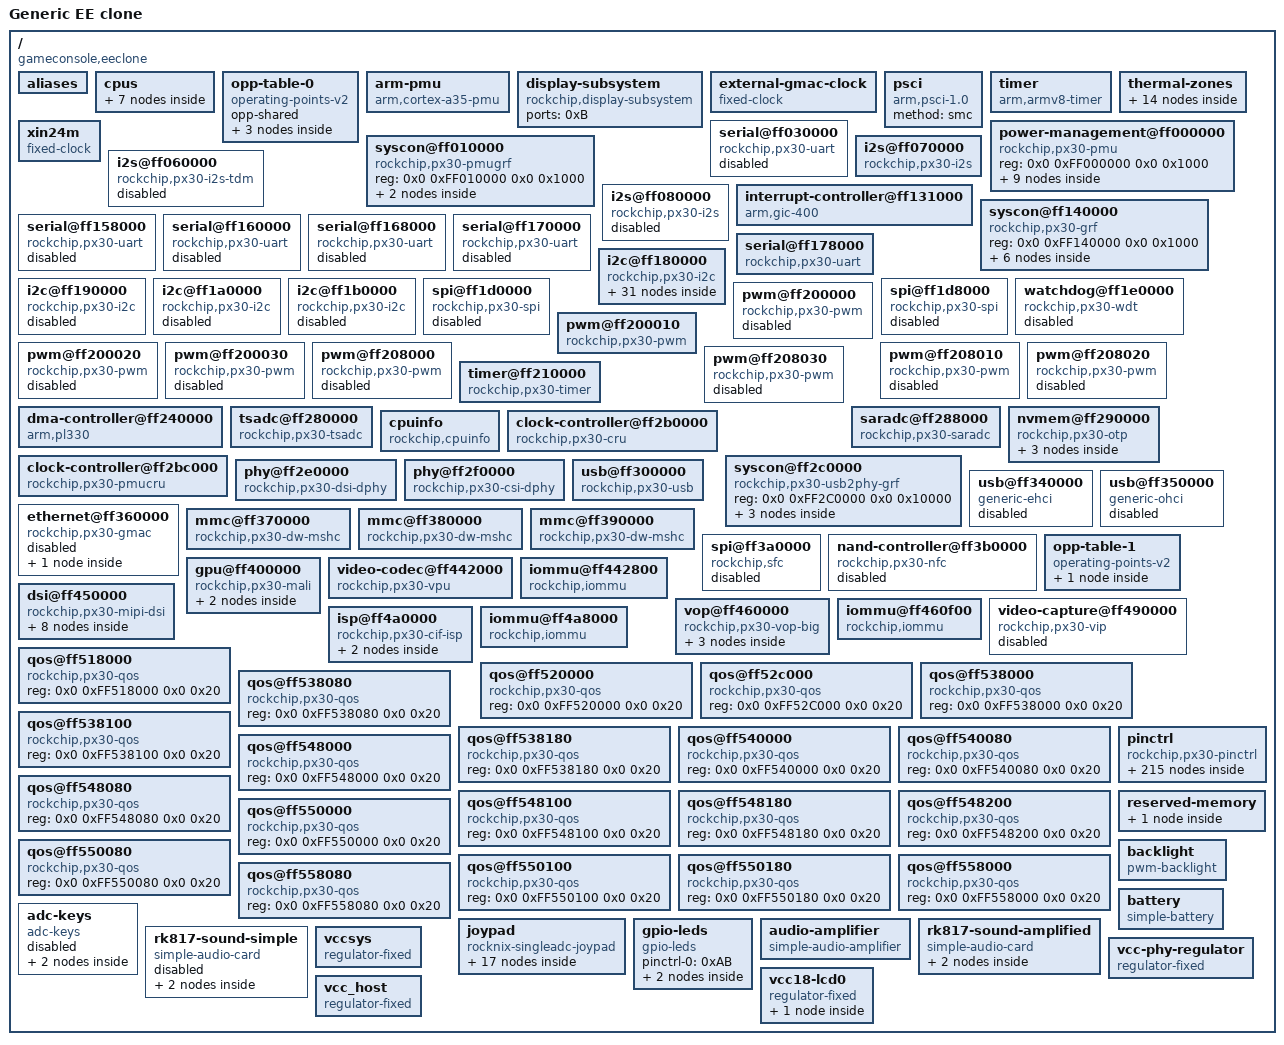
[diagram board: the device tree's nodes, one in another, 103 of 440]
/dts-v1/;
// version: 17
// last_comp_version: 16
// boot_cpuid_phys: 0x0

/ {
    compatible = "gameconsole,eeclone", "rockchip,rk3326";
    interrupt-parent = <0x1>;
    #address-cells = <0x2>;
    #size-cells = <0x2>;
    model = "Generic EE clone";
    aliases {
        i2c0 = "/i2c@ff180000";
        i2c1 = "/i2c@ff190000";
        i2c2 = "/i2c@ff1a0000";
        i2c3 = "/i2c@ff1b0000";
        serial0 = "/serial@ff030000";
        serial1 = "/serial@ff160000";
        serial2 = "/serial@ff178000";
        serial3 = "/serial@ff168000";
        serial4 = "/serial@ff170000";
        serial5 = "/serial@ff178000";
        spi0 = "/spi@ff1d0000";
        spi1 = "/spi@ff1d8000";
        mmc0 = "/mmc@ff390000";
        mmc1 = "/mmc@ff370000";
        mmc2 = "/mmc@ff380000";
    };
    cpus {
        #address-cells = <0x2>;
        #size-cells = <0x0>;
        cpu@0 {
            device_type = "cpu";
            compatible = "arm,cortex-a35";
            reg = <0x0 0x0>;
            enable-method = "psci";
            clocks = <0x2 0x7>;
            #cooling-cells = <0x2>;
            cpu-idle-states = <0x3 0x4>;
            dynamic-power-coefficient = <0x5A>;
            operating-points-v2 = <0x5>;
            cpu-supply = <0x6>;
            phandle = <0x7>;
        };
        cpu@1 {
            device_type = "cpu";
            compatible = "arm,cortex-a35";
            reg = <0x0 0x1>;
            enable-method = "psci";
            clocks = <0x2 0x7>;
            #cooling-cells = <0x2>;
            cpu-idle-states = <0x3 0x4>;
            dynamic-power-coefficient = <0x5A>;
            operating-points-v2 = <0x5>;
            cpu-supply = <0x6>;
            phandle = <0x8>;
        };
        cpu@2 {
            device_type = "cpu";
            compatible = "arm,cortex-a35";
            reg = <0x0 0x2>;
            enable-method = "psci";
            clocks = <0x2 0x7>;
            #cooling-cells = <0x2>;
            cpu-idle-states = <0x3 0x4>;
            dynamic-power-coefficient = <0x5A>;
            operating-points-v2 = <0x5>;
            cpu-supply = <0x6>;
            phandle = <0x9>;
        };
        cpu@3 {
            device_type = "cpu";
            compatible = "arm,cortex-a35";
            reg = <0x0 0x3>;
            enable-method = "psci";
            clocks = <0x2 0x7>;
            #cooling-cells = <0x2>;
            cpu-idle-states = <0x3 0x4>;
            dynamic-power-coefficient = <0x5A>;
            operating-points-v2 = <0x5>;
            cpu-supply = <0x6>;
            phandle = <0xA>;
        };
        idle-states {
            entry-method = "psci";
            cpu-sleep {
                compatible = "arm,idle-state";
                local-timer-stop;
                arm,psci-suspend-param = <0x10000>;
                entry-latency-us = <0x78>;
                exit-latency-us = <0xFA>;
                min-residency-us = <0x384>;
                phandle = <0x3>;
            };
            cluster-sleep {
                compatible = "arm,idle-state";
                local-timer-stop;
                arm,psci-suspend-param = <0x1010000>;
                entry-latency-us = <0x190>;
                exit-latency-us = <0x1F4>;
                min-residency-us = <0x7D0>;
                phandle = <0x4>;
            };
        };
    };
    opp-table-0 {
        compatible = "operating-points-v2";
        opp-shared;
        phandle = <0x5>;
        opp-1008000000 {
            opp-hz = <0x0 0x3C14DC00>;
            opp-microvolt = <0x11EDD8 0x11EDD8 0x149970>;
            clock-latency-ns = <0x9C40>;
        };
        opp-1296000000 {
            opp-hz = <0x0 0x4D3F6400>;
            opp-microvolt = <0x149970 0x149970 0x149970>;
            clock-latency-ns = <0x9C40>;
        };
        opp-1416000000 {
            opp-hz = <0x0 0x54667200>;
            opp-microvolt = <0x149970 0x149970 0x149970>;
            clock-latency-ns = <0x9C40>;
            turbo-mode;
        };
    };
    arm-pmu {
        compatible = "arm,cortex-a35-pmu";
        interrupts = <0x0 0x64 0x4 0x0 0x65 0x4 0x0 0x66 0x4 0x0 0x67 0x4>;
        interrupt-affinity = <0x7 0x8 0x9 0xA>;
    };
    display-subsystem {
        compatible = "rockchip,display-subsystem";
        ports = <0xB>;
        status = "okay";
        phandle = <0xB4>;
    };
    external-gmac-clock {
        compatible = "fixed-clock";
        clock-frequency = <0x2FAF080>;
        clock-output-names = "gmac_clkin";
        #clock-cells = <0x0>;
        phandle = <0xB5>;
    };
    psci {
        compatible = "arm,psci-1.0";
        method = "smc";
    };
    timer {
        compatible = "arm,armv8-timer";
        interrupts = <0x1 0xD 0xF04 0x1 0xE 0xF04 0x1 0xB 0xF04 0x1 0xA 0xF04>;
    };
    thermal-zones {
        phandle = <0xB6>;
        soc-thermal {
            polling-delay-passive = <0x14>;
            polling-delay = <0x3E8>;
            sustainable-power = <0x2EE>;
            thermal-sensors = <0xC 0x0>;
            phandle = <0xB7>;
            trips {
                trip-point-0 {
                    temperature = <0x11170>;
                    hysteresis = <0x7D0>;
                    type = "passive";
                    phandle = <0xB8>;
                };
                trip-point-1 {
                    temperature = <0x14C08>;
                    hysteresis = <0x7D0>;
                    type = "passive";
                    phandle = <0xD>;
                };
                soc-crit {
                    temperature = <0x1C138>;
                    hysteresis = <0x7D0>;
                    type = "critical";
                    phandle = <0xB9>;
                };
            };
            cooling-maps {
                map0 {
                    trip = <0xD>;
                    cooling-device = <0x7 0xFFFFFFFF 0xFFFFFFFF>;
                    contribution = <0x1000>;
                };
            };
        };
        gpu-thermal {
            polling-delay-passive = <0x64>;
            polling-delay = <0x3E8>;
            thermal-sensors = <0xC 0x1>;
            phandle = <0xBA>;
            trips {
                gpu-threshold {
                    temperature = <0x11170>;
                    hysteresis = <0x7D0>;
                    type = "passive";
                    phandle = <0xBB>;
                };
                gpu-target {
                    temperature = <0x14C08>;
                    hysteresis = <0x7D0>;
                    type = "passive";
                    phandle = <0xE>;
                };
                gpu-crit {
                    temperature = <0x1C138>;
                    hysteresis = <0x7D0>;
                    type = "critical";
                    phandle = <0xBC>;
                };
            };
            cooling-maps {
                map0 {
                    trip = <0xE>;
                    cooling-device = <0xF 0xFFFFFFFF 0xFFFFFFFF>;
                };
            };
        };
    };
    xin24m {
        compatible = "fixed-clock";
        #clock-cells = <0x0>;
        clock-frequency = <0x16E3600>;
        clock-output-names = "xin24m";
        phandle = <0x6F>;
    };
    power-management@ff000000 {
        compatible = "rockchip,px30-pmu", "syscon", "simple-mfd";
        reg = <0x0 0xFF000000 0x0 0x1000>;
        phandle = <0xBD>;
        power-controller {
            compatible = "rockchip,px30-power-controller";
            #power-domain-cells = <0x1>;
            #address-cells = <0x1>;
            #size-cells = <0x0>;
            phandle = <0x71>;
            power-domain@5 {
                reg = <0x5>;
                clocks = <0x2 0x103 0x2 0x102 0x2 0x3C>;
                pm_qos = <0x10 0x11>;
                #power-domain-cells = <0x0>;
            };
            power-domain@7 {
                reg = <0x7>;
                clocks = <0x2 0xF7 0x2 0x3B>;
                pm_qos = <0x12>;
                #power-domain-cells = <0x0>;
            };
            power-domain@9 {
                reg = <0x9>;
                clocks = <0x2 0xB2 0x2 0x143 0x2 0x40 0x2 0x3F>;
                pm_qos = <0x13>;
                #power-domain-cells = <0x0>;
            };
            power-domain@10 {
                reg = <0xA>;
                clocks = <0x2 0xFE 0x2 0x100 0x2 0xFF 0x2 0x101 0x2 0x39 0x2 0x37 0x2 0x38 0x2 0x3A>;
                pm_qos = <0x14 0x15 0x16 0x17>;
                #power-domain-cells = <0x0>;
            };
            power-domain@11 {
                reg = <0xB>;
                clocks = <0x2 0xAF 0x2 0xF4 0x2 0x4B>;
                pm_qos = <0x18 0x19>;
                #power-domain-cells = <0x0>;
            };
            power-domain@12 {
                reg = <0xC>;
                clocks = <0x2 0xB7 0x2 0xB5 0x2 0xB6 0x2 0x96 0x2 0x97 0x2 0xFD 0x2 0xFB 0x2 0xFC 0x2 0x144 0x2 0x35 0x2 0x36>;
                pm_qos = <0x1A 0x1B 0x1C 0x1D>;
                #power-domain-cells = <0x0>;
            };
            power-domain@13 {
                reg = <0xD>;
                clocks = <0x2 0xB3 0x2 0xB4 0x2 0xF9 0x2 0xFA 0x2 0x33>;
                pm_qos = <0x1E 0x1F 0x20 0x21 0x22>;
                #power-domain-cells = <0x0>;
            };
            power-domain@14 {
                reg = <0xE>;
                clocks = <0x2 0x49>;
                pm_qos = <0x23>;
                #power-domain-cells = <0x0>;
            };
        };
    };
    syscon@ff010000 {
        compatible = "rockchip,px30-pmugrf", "syscon", "simple-mfd";
        reg = <0x0 0xFF010000 0x0 0x1000>;
        phandle = <0x9C>;
        io-domains {
            compatible = "rockchip,px30-pmu-io-voltage-domain";
            status = "okay";
            pmuio1-supply = <0x24>;
            pmuio2-supply = <0x24>;
            phandle = <0xBE>;
        };
        reboot-mode {
            compatible = "syscon-reboot-mode";
            offset = <0x200>;
            mode-bootloader = <0x5242C301>;
            mode-fastboot = <0x5242C309>;
            mode-loader = <0x5242C301>;
            mode-normal = <0x5242C300>;
            mode-recovery = <0x5242C303>;
        };
    };
    serial@ff030000 {
        compatible = "rockchip,px30-uart", "snps,dw-apb-uart";
        reg = <0x0 0xFF030000 0x0 0x100>;
        interrupts = <0x0 0xF 0x4>;
        clocks = <0x25 0x6 0x25 0x15>;
        clock-names = "baudclk", "apb_pclk";
        dmas = <0x26 0x0 0x26 0x1>;
        dma-names = "tx", "rx";
        reg-shift = <0x2>;
        reg-io-width = <0x4>;
        pinctrl-names = "default";
        pinctrl-0 = <0x27 0x28 0x29>;
        status = "disabled";
        phandle = <0xBF>;
    };
    i2s@ff060000 {
        compatible = "rockchip,px30-i2s-tdm";
        reg = <0x0 0xFF060000 0x0 0x1000>;
        interrupts = <0x0 0xC 0x4>;
        clocks = <0x2 0x10 0x2 0x12 0x2 0x106>;
        clock-names = "mclk_tx", "mclk_rx", "hclk";
        dmas = <0x26 0x10 0x26 0x11>;
        dma-names = "tx", "rx";
        rockchip,grf = <0x2A>;
        resets = <0x2 0x84 0x2 0xBF>;
        reset-names = "tx-m", "rx-m";
        pinctrl-names = "default";
        pinctrl-0 = <0x2B 0x2C 0x2D 0x2E 0x2F 0x30 0x31 0x32 0x33 0x34 0x35 0x36>;
        #sound-dai-cells = <0x0>;
        status = "disabled";
        phandle = <0xC0>;
    };
    i2s@ff070000 {
        compatible = "rockchip,px30-i2s", "rockchip,rk3066-i2s";
        reg = <0x0 0xFF070000 0x0 0x1000>;
        interrupts = <0x0 0xD 0x4>;
        clocks = <0x2 0x14 0x2 0x107>;
        clock-names = "i2s_clk", "i2s_hclk";
        dmas = <0x26 0x12 0x26 0x13>;
        dma-names = "tx", "rx";
        pinctrl-names = "default";
        pinctrl-0 = <0x37 0x38 0x39 0x3A>;
        #sound-dai-cells = <0x0>;
        status = "okay";
        phandle = <0xB0>;
    };
    i2s@ff080000 {
        compatible = "rockchip,px30-i2s", "rockchip,rk3066-i2s";
        reg = <0x0 0xFF080000 0x0 0x1000>;
        interrupts = <0x0 0xE 0x4>;
        clocks = <0x2 0x16 0x2 0x108>;
        clock-names = "i2s_clk", "i2s_hclk";
        dmas = <0x26 0x14 0x26 0x15>;
        dma-names = "tx", "rx";
        pinctrl-names = "default";
        pinctrl-0 = <0x3B 0x3C 0x3D 0x3E>;
        #sound-dai-cells = <0x0>;
        status = "disabled";
        phandle = <0xC1>;
    };
    interrupt-controller@ff131000 {
        compatible = "arm,gic-400";
        #interrupt-cells = <0x3>;
        #address-cells = <0x0>;
        interrupt-controller;
        reg = <0x0 0xFF131000 0x0 0x1000 0x0 0xFF132000 0x0 0x2000 0x0 0xFF134000 0x0 0x2000 0x0 0xFF136000 0x0 0x2000>;
        interrupts = <0x1 0x9 0xF04>;
        phandle = <0x1>;
    };
    syscon@ff140000 {
        compatible = "rockchip,px30-grf", "syscon", "simple-mfd";
        reg = <0x0 0xFF140000 0x0 0x1000>;
        phandle = <0x2A>;
        io-domains {
            compatible = "rockchip,px30-io-voltage-domain";
            status = "okay";
            vccio1-supply = <0x3F>;
            vccio2-supply = <0x40>;
            vccio3-supply = <0x41>;
            vccio4-supply = <0x42>;
            vccio5-supply = <0x42>;
            vccio6-supply = <0x41>;
            phandle = <0xC2>;
        };
        lvds {
            compatible = "rockchip,px30-lvds";
            phys = <0x43>;
            phy-names = "dphy";
            rockchip,grf = <0x2A>;
            rockchip,output = "lvds";
            status = "disabled";
            phandle = <0xC3>;
            ports {
                #address-cells = <0x1>;
                #size-cells = <0x0>;
                port@0 {
                    reg = <0x0>;
                    #address-cells = <0x1>;
                    #size-cells = <0x0>;
                    phandle = <0xC4>;
                    endpoint@0 {
                        reg = <0x0>;
                        remote-endpoint = <0x44>;
                        phandle = <0x99>;
                    };
                };
                port@1 {
                    reg = <0x1>;
                    phandle = <0xC5>;
                };
            };
        };
    };
    serial@ff158000 {
        compatible = "rockchip,px30-uart", "snps,dw-apb-uart";
        reg = <0x0 0xFF158000 0x0 0x100>;
        interrupts = <0x0 0x10 0x4>;
        clocks = <0x2 0x18 0x2 0x149>;
        clock-names = "baudclk", "apb_pclk";
        dmas = <0x26 0x2 0x26 0x3>;
        dma-names = "tx", "rx";
        reg-shift = <0x2>;
        reg-io-width = <0x4>;
        pinctrl-names = "default";
        pinctrl-0 = <0x45 0x46 0x47>;
        status = "disabled";
        phandle = <0xC6>;
    };
    serial@ff160000 {
        compatible = "rockchip,px30-uart", "snps,dw-apb-uart";
        reg = <0x0 0xFF160000 0x0 0x100>;
        interrupts = <0x0 0x11 0x4>;
        clocks = <0x2 0x19 0x2 0x14A>;
        clock-names = "baudclk", "apb_pclk";
        dmas = <0x26 0x4 0x26 0x5>;
        dma-names = "tx", "rx";
        reg-shift = <0x2>;
        reg-io-width = <0x4>;
        pinctrl-names = "default";
        pinctrl-0 = <0x48>;
        status = "disabled";
        phandle = <0xC7>;
    };
    serial@ff168000 {
        compatible = "rockchip,px30-uart", "snps,dw-apb-uart";
        reg = <0x0 0xFF168000 0x0 0x100>;
        interrupts = <0x0 0x12 0x4>;
        clocks = <0x2 0x1A 0x2 0x14B>;
        clock-names = "baudclk", "apb_pclk";
        dmas = <0x26 0x6 0x26 0x7>;
        dma-names = "tx", "rx";
        reg-shift = <0x2>;
        reg-io-width = <0x4>;
        pinctrl-names = "default";
        pinctrl-0 = <0x49 0x4A 0x4B>;
        status = "disabled";
        phandle = <0xC8>;
    };
    serial@ff170000 {
        compatible = "rockchip,px30-uart", "snps,dw-apb-uart";
        reg = <0x0 0xFF170000 0x0 0x100>;
        interrupts = <0x0 0x13 0x4>;
        clocks = <0x2 0x1B 0x2 0x14C>;
        clock-names = "baudclk", "apb_pclk";
        dmas = <0x26 0x8 0x26 0x9>;
        dma-names = "tx", "rx";
        reg-shift = <0x2>;
        reg-io-width = <0x4>;
        pinctrl-names = "default";
        pinctrl-0 = <0x4C 0x4D 0x4E>;
        status = "disabled";
        phandle = <0xC9>;
    };
    serial@ff178000 {
        compatible = "rockchip,px30-uart", "snps,dw-apb-uart";
        reg = <0x0 0xFF178000 0x0 0x100>;
        interrupts = <0x0 0x14 0x4>;
        clocks = <0x2 0x1C 0x2 0x14D>;
        clock-names = "baudclk", "apb_pclk";
        dmas = <0x26 0xA 0x26 0xB>;
        dma-names = "tx", "rx";
        reg-shift = <0x2>;
        reg-io-width = <0x4>;
        pinctrl-names = "default";
        pinctrl-0 = <0x4F 0x50 0x51>;
        status = "okay";
        phandle = <0xCA>;
    };
    i2c@ff180000 {
        compatible = "rockchip,px30-i2c", "rockchip,rk3399-i2c";
        reg = <0x0 0xFF180000 0x0 0x1000>;
        clocks = <0x2 0x1D 0x2 0x14E>;
        clock-names = "i2c", "pclk";
        interrupts = <0x0 0x7 0x4>;
        pinctrl-names = "default";
        pinctrl-0 = <0x52>;
        #address-cells = <0x1>;
        #size-cells = <0x0>;
        status = "okay";
        clock-frequency = <0x61A80>;
        i2c-scl-falling-time-ns = <0x10>;
        i2c-scl-rising-time-ns = <0x118>;
        phandle = <0xCB>;
        pmic@20 {
            compatible = "rockchip,rk817";
            reg = <0x20>;
            interrupt-parent = <0x53>;
            interrupts = <0xA 0x8>;
            clock-output-names = "rk808-clkout1", "xin32k";
            clock-names = "mclk";
            clocks = <0x2 0x15>;
            pinctrl-names = "default";
            pinctrl-0 = <0x54 0x55>;
            rockchip,system-power-controller;
            wakeup-source;
            #clock-cells = <0x1>;
            #sound-dai-cells = <0x0>;
            vcc1-supply = <0x56>;
            vcc2-supply = <0x56>;
            vcc3-supply = <0x56>;
            vcc4-supply = <0x56>;
            vcc5-supply = <0x56>;
            vcc6-supply = <0x56>;
            vcc7-supply = <0x42>;
            vcc8-supply = <0x56>;
            phandle = <0xAF>;
            regulators {
                DCDC_REG1 {
                    regulator-name = "vdd_logic";
                    regulator-min-microvolt = <0xE7EF0>;
                    regulator-max-microvolt = <0x149970>;
                    regulator-initial-mode = <0x2>;
                    regulator-ramp-delay = <0x1771>;
                    regulator-always-on;
                    regulator-boot-on;
                    phandle = <0x8E>;
                    regulator-state-mem {
                        regulator-on-in-suspend;
                        regulator-suspend-microvolt = <0xE7EF0>;
                    };
                };
                DCDC_REG2 {
                    regulator-name = "vdd_arm";
                    regulator-min-microvolt = <0xCF850>;
                    regulator-max-microvolt = <0x149970>;
                    regulator-ramp-delay = <0x1771>;
                    regulator-initial-mode = <0x2>;
                    regulator-always-on;
                    regulator-boot-on;
                    phandle = <0x6>;
                    regulator-state-mem {
                        regulator-off-in-suspend;
                        regulator-suspend-microvolt = <0xE7EF0>;
                    };
                };
                DCDC_REG3 {
                    regulator-name = "vcc_ddr";
                    regulator-always-on;
                    regulator-boot-on;
                    regulator-initial-mode = <0x2>;
                    phandle = <0xCC>;
                    regulator-state-mem {
                        regulator-on-in-suspend;
                    };
                };
                DCDC_REG4 {
                    regulator-name = "vcc_3v0";
                    regulator-min-microvolt = <0x2DC6C0>;
                    regulator-max-microvolt = <0x2DC6C0>;
                    regulator-initial-mode = <0x2>;
                    regulator-always-on;
                    regulator-boot-on;
                    phandle = <0x42>;
                    regulator-state-mem {
                        regulator-off-in-suspend;
                        regulator-suspend-microvolt = <0x2DC6C0>;
                    };
                };
                LDO_REG1 {
                    regulator-name = "vcc_1v0";
                    regulator-always-on;
                    regulator-boot-on;
                    regulator-min-microvolt = <0xF4240>;
                    regulator-max-microvolt = <0xF4240>;
                    phandle = <0xCD>;
                    regulator-state-mem {
                        regulator-on-in-suspend;
                        regulator-suspend-microvolt = <0xF4240>;
                    };
                };
                LDO_REG2 {
                    regulator-name = "vcc1v8_soc";
                    regulator-min-microvolt = <0x1B7740>;
                    regulator-max-microvolt = <0x1B7740>;
                    regulator-always-on;
                    regulator-boot-on;
                    phandle = <0x41>;
                    regulator-state-mem {
                        regulator-on-in-suspend;
                        regulator-suspend-microvolt = <0x1B7740>;
                    };
                };
                LDO_REG3 {
                    regulator-name = "vcc1v0_soc";
                    regulator-min-microvolt = <0xF4240>;
                    regulator-max-microvolt = <0xF4240>;
                    regulator-always-on;
                    regulator-boot-on;
                    phandle = <0xCE>;
                    regulator-state-mem {
                        regulator-on-in-suspend;
                        regulator-suspend-microvolt = <0xF4240>;
                    };
                };
                LDO_REG4 {
                    regulator-name = "vcc3v0_pmu";
                    regulator-min-microvolt = <0x2DC6C0>;
                    regulator-max-microvolt = <0x2DC6C0>;
                    regulator-always-on;
                    regulator-boot-on;
                    phandle = <0x24>;
                    regulator-state-mem {
                        regulator-on-in-suspend;
                        regulator-suspend-microvolt = <0x2DC6C0>;
                    };
                };
                LDO_REG5 {
                    regulator-name = "vccio_sd";
                    regulator-min-microvolt = <0x1B7740>;
                    regulator-max-microvolt = <0x325AA0>;
                    regulator-always-on;
                    regulator-boot-on;
                    phandle = <0x40>;
                    regulator-state-mem {
                        regulator-on-in-suspend;
                        regulator-suspend-microvolt = <0x325AA0>;
                    };
                };
                LDO_REG6 {
                    regulator-name = "vcc_sd";
                    regulator-min-microvolt = <0x1B7740>;
                    regulator-max-microvolt = <0x325AA0>;
                    phandle = <0x7A>;
                    regulator-state-mem {
                        regulator-on-in-suspend;
                        regulator-suspend-microvolt = <0x325AA0>;
                    };
                };
                LDO_REG7 {
                    regulator-name = "vcc2v8_dvp";
                    regulator-min-microvolt = <0x1B7740>;
                    regulator-max-microvolt = <0x325AA0>;
                    regulator-always-on;
                    regulator-boot-on;
                    phandle = <0x3F>;
                    regulator-state-mem {
                        regulator-off-in-suspend;
                        regulator-suspend-microvolt = <0x325AA0>;
                    };
                };
                LDO_REG8 {
                    regulator-name = "vcc3v0_dvp";
                    regulator-min-microvolt = <0x2DC6C0>;
                    regulator-max-microvolt = <0x2DC6C0>;
                    regulator-always-on;
                    regulator-boot-on;
                    phandle = <0x7E>;
                    regulator-state-mem {
                        regulator-on-in-suspend;
                        regulator-suspend-microvolt = <0x2DC6C0>;
                    };
                };
                LDO_REG9 {
                    regulator-min-microvolt = <0x16E360>;
                    regulator-max-microvolt = <0x16E360>;
                    regulator-name = "vdd1v5_dvp";
                    regulator-always-on;
                    regulator-boot-on;
                    phandle = <0xCF>;
                    regulator-state-mem {
                        regulator-off-in-suspend;
                        regulator-suspend-microvolt = <0x16E360>;
                    };
                };
                BOOST {
                    regulator-name = "usb_midu";
                    regulator-min-microvolt = <0x4AC4A0>;
                    regulator-max-microvolt = <0x5265C0>;
                    regulator-always-on;
                    regulator-boot-on;
                    phandle = <0xB3>;
                };
            };
            charger {
                monitored-battery = <0x57>;
                rockchip,resistor-sense-micro-ohms = <0x2710>;
                rockchip,sleep-enter-current-microamp = <0x493E0>;
                rockchip,sleep-filter-current-microamp = <0x186A0>;
                phandle = <0xD0>;
            };
            codec {
                rockchip,mic-in-differential;
                phandle = <0xD1>;
            };
        };
    };
    i2c@ff190000 {
        compatible = "rockchip,px30-i2c", "rockchip,rk3399-i2c";
        reg = <0x0 0xFF190000 0x0 0x1000>;
        clocks = <0x2 0x1E 0x2 0x14F>;
        clock-names = "i2c", "pclk";
        interrupts = <0x0 0x8 0x4>;
        pinctrl-names = "default";
        pinctrl-0 = <0x58>;
        #address-cells = <0x1>;
        #size-cells = <0x0>;
        status = "disabled";
        phandle = <0xD2>;
    };
    i2c@ff1a0000 {
        compatible = "rockchip,px30-i2c", "rockchip,rk3399-i2c";
        reg = <0x0 0xFF1A0000 0x0 0x1000>;
        clocks = <0x2 0x1F 0x2 0x150>;
        clock-names = "i2c", "pclk";
        interrupts = <0x0 0x9 0x4>;
        pinctrl-names = "default";
        pinctrl-0 = <0x59>;
        #address-cells = <0x1>;
        #size-cells = <0x0>;
        status = "disabled";
        phandle = <0xD3>;
    };
    i2c@ff1b0000 {
        compatible = "rockchip,px30-i2c", "rockchip,rk3399-i2c";
        reg = <0x0 0xFF1B0000 0x0 0x1000>;
        clocks = <0x2 0x20 0x2 0x151>;
        clock-names = "i2c", "pclk";
        interrupts = <0x0 0xA 0x4>;
        pinctrl-names = "default";
        pinctrl-0 = <0x5A>;
        #address-cells = <0x1>;
        #size-cells = <0x0>;
        status = "disabled";
        phandle = <0xD4>;
    };
    spi@ff1d0000 {
        compatible = "rockchip,px30-spi", "rockchip,rk3066-spi";
        reg = <0x0 0xFF1D0000 0x0 0x1000>;
        interrupts = <0x0 0x1A 0x4>;
        clocks = <0x2 0x24 0x2 0x155>;
        clock-names = "spiclk", "apb_pclk";
        dmas = <0x26 0xC 0x26 0xD>;
        dma-names = "tx", "rx";
        num-cs = <0x2>;
        pinctrl-names = "default";
        pinctrl-0 = <0x5B 0x5C 0x5D 0x5E>;
        #address-cells = <0x1>;
        #size-cells = <0x0>;
        status = "disabled";
        phandle = <0xD5>;
    };
    spi@ff1d8000 {
        compatible = "rockchip,px30-spi", "rockchip,rk3066-spi";
        reg = <0x0 0xFF1D8000 0x0 0x1000>;
        interrupts = <0x0 0x1B 0x4>;
        clocks = <0x2 0x25 0x2 0x156>;
        clock-names = "spiclk", "apb_pclk";
        dmas = <0x26 0xE 0x26 0xF>;
        dma-names = "tx", "rx";
        num-cs = <0x2>;
        pinctrl-names = "default";
        pinctrl-0 = <0x5F 0x60 0x61 0x62 0x63>;
        #address-cells = <0x1>;
        #size-cells = <0x0>;
        status = "disabled";
        phandle = <0xD6>;
    };
    watchdog@ff1e0000 {
        compatible = "rockchip,px30-wdt", "snps,dw-wdt";
        reg = <0x0 0xFF1E0000 0x0 0x100>;
        clocks = <0x2 0x15B>;
        interrupts = <0x0 0x25 0x4>;
        status = "disabled";
        phandle = <0xD7>;
    };
    pwm@ff200000 {
        compatible = "rockchip,px30-pwm", "rockchip,rk3328-pwm";
        reg = <0x0 0xFF200000 0x0 0x10>;
        clocks = <0x2 0x22 0x2 0x153>;
        clock-names = "pwm", "pclk";
        pinctrl-names = "default";
        pinctrl-0 = <0x64>;
        #pwm-cells = <0x3>;
        status = "disabled";
        phandle = <0xD8>;
    };
    pwm@ff200010 {
        compatible = "rockchip,px30-pwm", "rockchip,rk3328-pwm";
        reg = <0x0 0xFF200010 0x0 0x10>;
        clocks = <0x2 0x22 0x2 0x153>;
        clock-names = "pwm", "pclk";
        pinctrl-names = "default";
        pinctrl-0 = <0x65>;
        #pwm-cells = <0x3>;
        status = "okay";
        phandle = <0xA7>;
    };
    pwm@ff200020 {
        compatible = "rockchip,px30-pwm", "rockchip,rk3328-pwm";
        reg = <0x0 0xFF200020 0x0 0x10>;
        clocks = <0x2 0x22 0x2 0x153>;
        clock-names = "pwm", "pclk";
        pinctrl-names = "default";
        pinctrl-0 = <0x66>;
        #pwm-cells = <0x3>;
        status = "disabled";
        phandle = <0xD9>;
    };
    pwm@ff200030 {
        compatible = "rockchip,px30-pwm", "rockchip,rk3328-pwm";
        reg = <0x0 0xFF200030 0x0 0x10>;
        clocks = <0x2 0x22 0x2 0x153>;
        clock-names = "pwm", "pclk";
        pinctrl-names = "default";
        pinctrl-0 = <0x67>;
        #pwm-cells = <0x3>;
        status = "disabled";
        phandle = <0xDA>;
    };
    pwm@ff208000 {
        compatible = "rockchip,px30-pwm", "rockchip,rk3328-pwm";
        reg = <0x0 0xFF208000 0x0 0x10>;
        clocks = <0x2 0x23 0x2 0x154>;
        clock-names = "pwm", "pclk";
        pinctrl-names = "default";
        pinctrl-0 = <0x68>;
        #pwm-cells = <0x3>;
        status = "disabled";
        phandle = <0xDB>;
    };
    pwm@ff208010 {
        compatible = "rockchip,px30-pwm", "rockchip,rk3328-pwm";
        reg = <0x0 0xFF208010 0x0 0x10>;
        clocks = <0x2 0x23 0x2 0x154>;
        clock-names = "pwm", "pclk";
        pinctrl-names = "default";
        pinctrl-0 = <0x69>;
        #pwm-cells = <0x3>;
        status = "disabled";
        phandle = <0xDC>;
    };
    pwm@ff208020 {
        compatible = "rockchip,px30-pwm", "rockchip,rk3328-pwm";
        reg = <0x0 0xFF208020 0x0 0x10>;
        clocks = <0x2 0x23 0x2 0x154>;
        clock-names = "pwm", "pclk";
        pinctrl-names = "default";
        pinctrl-0 = <0x6A>;
        #pwm-cells = <0x3>;
        status = "disabled";
        phandle = <0xDD>;
    };
    pwm@ff208030 {
        compatible = "rockchip,px30-pwm", "rockchip,rk3328-pwm";
        reg = <0x0 0xFF208030 0x0 0x10>;
        clocks = <0x2 0x23 0x2 0x154>;
        clock-names = "pwm", "pclk";
        pinctrl-names = "default";
        pinctrl-0 = <0x6B>;
        #pwm-cells = <0x3>;
        status = "disabled";
        phandle = <0xDE>;
    };
    timer@ff210000 {
        compatible = "rockchip,px30-timer", "rockchip,rk3288-timer";
        reg = <0x0 0xFF210000 0x0 0x1000>;
        interrupts = <0x0 0x1E 0x4>;
        clocks = <0x2 0x159 0x2 0x26>;
        clock-names = "pclk", "timer";
        phandle = <0xDF>;
    };
    dma-controller@ff240000 {
        compatible = "arm,pl330", "arm,primecell";
        reg = <0x0 0xFF240000 0x0 0x4000>;
        interrupts = <0x0 0x1 0x4 0x0 0x2 0x4>;
        arm,pl330-periph-burst;
        clocks = <0x2 0xBB>;
        clock-names = "apb_pclk";
        #dma-cells = <0x1>;
        phandle = <0x26>;
    };
    tsadc@ff280000 {
        compatible = "rockchip,px30-tsadc";
        reg = <0x0 0xFF280000 0x0 0x100>;
        interrupts = <0x0 0x24 0x4>;
        assigned-clocks = <0x2 0x2C>;
        assigned-clock-rates = <0xC350>;
        clocks = <0x2 0x2C 0x2 0x158>;
        clock-names = "tsadc", "apb_pclk";
        resets = <0x2 0xA8>;
        reset-names = "tsadc-apb";
        rockchip,grf = <0x2A>;
        rockchip,hw-tshut-temp = <0x1D4C0>;
        pinctrl-names = "init", "default", "sleep";
        pinctrl-0 = <0x6C>;
        pinctrl-1 = <0x6D>;
        pinctrl-2 = <0x6C>;
        #thermal-sensor-cells = <0x1>;
        status = "okay";
        phandle = <0xC>;
    };
    saradc@ff288000 {
        compatible = "rockchip,px30-saradc", "rockchip,rk3399-saradc";
        reg = <0x0 0xFF288000 0x0 0x100>;
        interrupts = <0x0 0x54 0x4>;
        #io-channel-cells = <0x1>;
        clocks = <0x2 0x2D 0x2 0x157>;
        clock-names = "saradc", "apb_pclk";
        resets = <0x2 0xA5>;
        reset-names = "saradc-apb";
        status = "okay";
        vref-supply = <0x41>;
        phandle = <0xA8>;
    };
    nvmem@ff290000 {
        compatible = "rockchip,px30-otp";
        reg = <0x0 0xFF290000 0x0 0x4000>;
        clocks = <0x2 0x2F 0x2 0x15A 0x2 0x161>;
        clock-names = "otp", "apb_pclk", "phy";
        resets = <0x2 0xB4>;
        reset-names = "phy";
        #address-cells = <0x1>;
        #size-cells = <0x1>;
        phandle = <0xE0>;
        id@7 {
            reg = <0x7 0x10>;
            phandle = <0x6E>;
        };
        cpu-leakage@17 {
            reg = <0x17 0x1>;
            phandle = <0xE1>;
        };
        performance@1e {
            reg = <0x1E 0x1>;
            bits = <0x4 0x3>;
            phandle = <0xE2>;
        };
    };
    cpuinfo {
        compatible = "rockchip,cpuinfo";
        nvmem-cells = <0x6E>;
        nvmem-cell-names = "id";
    };
    clock-controller@ff2b0000 {
        compatible = "rockchip,px30-cru";
        reg = <0x0 0xFF2B0000 0x0 0x1000>;
        clocks = <0x6F 0x25 0x1>;
        clock-names = "xin24m", "gpll";
        rockchip,grf = <0x2A>;
        #clock-cells = <0x1>;
        #reset-cells = <0x1>;
        assigned-clocks = <0x2 0x4 0x2 0xAB 0x2 0xB0 0x2 0xF0 0x2 0xF5 0x2 0x140 0x2 0x49>;
        assigned-clock-rates = <0x46CF7100 0xBEBC200 0xBEBC200 0x8F0D180 0x8F0D180 0x5F5E100 0xBEBC200>;
        phandle = <0x2>;
    };
    clock-controller@ff2bc000 {
        compatible = "rockchip,px30-pmucru";
        reg = <0x0 0xFF2BC000 0x0 0x1000>;
        clocks = <0x6F>;
        clock-names = "xin24m";
        rockchip,grf = <0x2A>;
        #clock-cells = <0x1>;
        #reset-cells = <0x1>;
        assigned-clocks = <0x25 0x1 0x25 0x8 0x25 0x5>;
        assigned-clock-rates = <0x47868C00 0x5F5E100 0x18CBA80>;
        phandle = <0x25>;
    };
    syscon@ff2c0000 {
        compatible = "rockchip,px30-usb2phy-grf", "syscon", "simple-mfd";
        reg = <0x0 0xFF2C0000 0x0 0x10000>;
        #address-cells = <0x1>;
        #size-cells = <0x1>;
        phandle = <0xE3>;
        usb2phy@100 {
            compatible = "rockchip,px30-usb2phy";
            reg = <0x100 0x20>;
            clocks = <0x25 0xA>;
            clock-names = "phyclk";
            #clock-cells = <0x0>;
            assigned-clocks = <0x2 0xE>;
            assigned-clock-parents = <0x70>;
            clock-output-names = "usb480m_phy";
            status = "okay";
            phandle = <0x70>;
            host-port {
                #phy-cells = <0x0>;
                interrupts = <0x0 0x44 0x4>;
                interrupt-names = "linestate";
                status = "okay";
                phandle = <0x73>;
            };
            otg-port {
                #phy-cells = <0x0>;
                interrupts = <0x0 0x42 0x4 0x0 0x41 0x4 0x0 0x40 0x4>;
                interrupt-names = "otg-bvalid", "otg-id", "linestate";
                status = "disabled";
                phandle = <0x72>;
            };
        };
    };
    phy@ff2e0000 {
        compatible = "rockchip,px30-dsi-dphy";
        reg = <0x0 0xFF2E0000 0x0 0x10000>;
        clocks = <0x25 0xB 0x2 0x145>;
        clock-names = "ref", "pclk";
        resets = <0x2 0x3E>;
        reset-names = "apb";
        #phy-cells = <0x0>;
        power-domains = <0x71 0xC>;
        status = "okay";
        phandle = <0x43>;
    };
    phy@ff2f0000 {
        compatible = "rockchip,px30-csi-dphy";
        reg = <0x0 0xFF2F0000 0x0 0x4000>;
        clocks = <0x2 0x146>;
        clock-names = "pclk";
        #phy-cells = <0x0>;
        power-domains = <0x71 0xD>;
        resets = <0x2 0x2F>;
        reset-names = "apb";
        rockchip,grf = <0x2A>;
        status = "okay";
        phandle = <0x9B>;
    };
    usb@ff300000 {
        compatible = "rockchip,px30-usb", "rockchip,rk3066-usb", "snps,dwc2";
        reg = <0x0 0xFF300000 0x0 0x40000>;
        interrupts = <0x0 0x3E 0x4>;
        clocks = <0x2 0x102>;
        clock-names = "otg";
        dr_mode = "otg";
        g-np-tx-fifo-size = <0x10>;
        g-rx-fifo-size = <0x118>;
        g-tx-fifo-size = <0x100 0x80 0x80 0x40 0x20 0x10>;
        phys = <0x72>;
        phy-names = "usb2-phy";
        power-domains = <0x71 0x5>;
        status = "okay";
        usb-role-switch;
        role-switch-default-mode = "host";
        phandle = <0xE4>;
    };
    usb@ff340000 {
        compatible = "generic-ehci";
        reg = <0x0 0xFF340000 0x0 0x10000>;
        interrupts = <0x0 0x3C 0x4>;
        clocks = <0x2 0x103>;
        phys = <0x73>;
        phy-names = "usb";
        power-domains = <0x71 0x5>;
        status = "disabled";
        phandle = <0xE5>;
    };
    usb@ff350000 {
        compatible = "generic-ohci";
        reg = <0x0 0xFF350000 0x0 0x10000>;
        interrupts = <0x0 0x3D 0x4>;
        clocks = <0x2 0x103>;
        phys = <0x73>;
        phy-names = "usb";
        power-domains = <0x71 0x5>;
        status = "disabled";
        phandle = <0xE6>;
    };
    ethernet@ff360000 {
        compatible = "rockchip,px30-gmac";
        reg = <0x0 0xFF360000 0x0 0x10000>;
        interrupts = <0x0 0x2B 0x4>;
        interrupt-names = "macirq";
        clocks = <0x2 0x3E 0x2 0x3F 0x2 0x3F 0x2 0x40 0x2 0x41 0x2 0xB2 0x2 0x143 0x2 0x4C>;
        clock-names = "stmmaceth", "mac_clk_rx", "mac_clk_tx", "clk_mac_ref", "clk_mac_refout", "aclk_mac", "pclk_mac", "clk_mac_speed";
        rockchip,grf = <0x2A>;
        phy-mode = "rmii";
        pinctrl-names = "default";
        pinctrl-0 = <0x74 0x75>;
        power-domains = <0x71 0x9>;
        resets = <0x2 0x5E>;
        reset-names = "stmmaceth";
        status = "disabled";
        phandle = <0xE7>;
        mdio {
            compatible = "snps,dwmac-mdio";
            #address-cells = <0x1>;
            #size-cells = <0x0>;
            phandle = <0xE8>;
        };
    };
    mmc@ff370000 {
        compatible = "rockchip,px30-dw-mshc", "rockchip,rk3288-dw-mshc";
        reg = <0x0 0xFF370000 0x0 0x4000>;
        interrupts = <0x0 0x36 0x4>;
        clocks = <0x2 0xF7 0x2 0x3B 0x2 0x43 0x2 0x44>;
        clock-names = "biu", "ciu", "ciu-drive", "ciu-sample";
        bus-width = <0x4>;
        fifo-depth = <0x100>;
        max-frequency = <0x8F0D180>;
        pinctrl-names = "default";
        pinctrl-0 = <0x76 0x77 0x78 0x79>;
        power-domains = <0x71 0x7>;
        status = "okay";
        cap-sd-highspeed;
        card-detect-delay = <0x320>;
        cd-gpios = <0x53 0x3 0x1>;
        sd-uhs-sdr12;
        sd-uhs-sdr25;
        sd-uhs-sdr50;
        sd-uhs-sdr104;
        vqmmc-supply = <0x40>;
        vmmc-supply = <0x7A>;
        phandle = <0xE9>;
    };
    mmc@ff380000 {
        compatible = "rockchip,px30-dw-mshc", "rockchip,rk3288-dw-mshc";
        reg = <0x0 0xFF380000 0x0 0x4000>;
        interrupts = <0x0 0x37 0x4>;
        clocks = <0x2 0xFF 0x2 0x38 0x2 0x45 0x2 0x46>;
        clock-names = "biu", "ciu", "ciu-drive", "ciu-sample";
        bus-width = <0x4>;
        fifo-depth = <0x100>;
        max-frequency = <0x5F5E100>;
        pinctrl-names = "default";
        pinctrl-0 = <0x7B 0x7C 0x7D>;
        power-domains = <0x71 0xA>;
        status = "okay";
        cap-sd-highspeed;
        cd-gpios = <0x53 0x2 0x1>;
        card-detect-delay = <0x320>;
        sd-uhs-sdr12;
        sd-uhs-sdr25;
        sd-uhs-sdr50;
        sd-uhs-sdr104;
        vqmmc-supply = <0x3F>;
        vmmc-supply = <0x7E>;
        phandle = <0xEA>;
    };
    mmc@ff390000 {
        compatible = "rockchip,px30-dw-mshc", "rockchip,rk3288-dw-mshc";
        reg = <0x0 0xFF390000 0x0 0x4000>;
        interrupts = <0x0 0x35 0x4>;
        clocks = <0x2 0x100 0x2 0x39 0x2 0x47 0x2 0x48>;
        clock-names = "biu", "ciu", "ciu-drive", "ciu-sample";
        bus-width = <0x8>;
        fifo-depth = <0x100>;
        max-frequency = <0x8F0D180>;
        pinctrl-names = "default";
        pinctrl-0 = <0x7F 0x80 0x81>;
        power-domains = <0x71 0xA>;
        status = "okay";
        no-sdio;
        no-sd;
        disable-wp;
        non-removable;
        num-slots = <0x1>;
        phandle = <0xEB>;
    };
    spi@ff3a0000 {
        compatible = "rockchip,sfc";
        reg = <0x0 0xFF3A0000 0x0 0x4000>;
        interrupts = <0x0 0x38 0x4>;
        clocks = <0x2 0x3A 0x2 0x101>;
        clock-names = "clk_sfc", "hclk_sfc";
        pinctrl-0 = <0x82 0x83 0x84>;
        pinctrl-names = "default";
        power-domains = <0x71 0xA>;
        status = "disabled";
        phandle = <0xEC>;
    };
    nand-controller@ff3b0000 {
        compatible = "rockchip,px30-nfc";
        reg = <0x0 0xFF3B0000 0x0 0x4000>;
        interrupts = <0x0 0x39 0x4>;
        clocks = <0x2 0xFE 0x2 0x37>;
        clock-names = "ahb", "nfc";
        assigned-clocks = <0x2 0x37>;
        assigned-clock-rates = <0x8F0D180>;
        pinctrl-names = "default";
        pinctrl-0 = <0x85 0x86 0x87 0x88 0x89 0x8A 0x8B 0x8C>;
        power-domains = <0x71 0xA>;
        status = "disabled";
        phandle = <0xED>;
    };
    opp-table-1 {
        compatible = "operating-points-v2";
        phandle = <0x8D>;
        opp-560000000 {
            opp-hz = <0x0 0x2160EC00>;
            opp-microvolt = <0x118C30>;
        };
    };
    gpu@ff400000 {
        compatible = "rockchip,px30-mali", "arm,mali-bifrost";
        reg = <0x0 0xFF400000 0x0 0x4000>;
        interrupts = <0x0 0x2F 0x4 0x0 0x2E 0x4 0x0 0x2D 0x4>;
        interrupt-names = "job", "mmu", "gpu";
        clocks = <0x2 0x49>;
        #cooling-cells = <0x2>;
        power-domains = <0x71 0xE>;
        operating-points-v2 = <0x8D>;
        status = "okay";
        clock-names = "bus";
        resets = <0x2 0x12>;
        power_policy = "coarse_demand";
        mali-supply = <0x8E>;
        phandle = <0xF>;
        power_model@0 {
            compatible = "arm,mali-simple-power-model";
            static-coefficient = <0x186A0>;
            dynamic-coefficient = <0x3B9>;
            ts = <0xFFFE56A6 0xF87A 0xFFFFFAB5 0x14>;
            thermal-zone = "gpu-thermal";
        };
        power_model@1 {
            compatible = "arm,mali-g31-power-model";
            scale = <0x5>;
        };
    };
    video-codec@ff442000 {
        compatible = "rockchip,px30-vpu";
        reg = <0x0 0xFF442000 0x0 0x800>;
        interrupts = <0x0 0x50 0x4 0x0 0x4F 0x4>;
        interrupt-names = "vepu", "vdpu";
        clocks = <0x2 0xAF 0x2 0xF4>;
        clock-names = "aclk", "hclk";
        iommus = <0x8F>;
        power-domains = <0x71 0xB>;
        phandle = <0xEE>;
    };
    iommu@ff442800 {
        compatible = "rockchip,iommu";
        reg = <0x0 0xFF442800 0x0 0x100>;
        interrupts = <0x0 0x51 0x4>;
        clocks = <0x2 0xAF 0x2 0xF4>;
        clock-names = "aclk", "iface";
        #iommu-cells = <0x0>;
        power-domains = <0x71 0xB>;
        phandle = <0x8F>;
    };
    dsi@ff450000 {
        compatible = "rockchip,px30-mipi-dsi", "snps,dw-mipi-dsi";
        reg = <0x0 0xFF450000 0x0 0x10000>;
        interrupts = <0x0 0x4B 0x4>;
        clocks = <0x2 0x144>;
        clock-names = "pclk";
        phys = <0x43>;
        phy-names = "dphy";
        power-domains = <0x71 0xC>;
        resets = <0x2 0x3D>;
        reset-names = "apb";
        rockchip,grf = <0x2A>;
        status = "okay";
        phandle = <0xEF>;
        ports {
            #address-cells = <0x1>;
            #size-cells = <0x0>;
            port@0 {
                reg = <0x0>;
                #address-cells = <0x1>;
                #size-cells = <0x0>;
                phandle = <0xF0>;
                endpoint@0 {
                    reg = <0x0>;
                    remote-endpoint = <0x90>;
                    phandle = <0x98>;
                };
            };
            port@1 {
                reg = <0x1>;
                phandle = <0xF1>;
                endpoint {
                    remote-endpoint = <0x91>;
                    phandle = <0x96>;
                };
            };
        };
        panel@0 {
            compatible = "rocknix,generic-dsi";
            iovcc-supply = <0x92>;
            vcc-supply = <0x92>;
            reg = <0x0>;
            backlight = <0x93>;
            reset-gpios = <0x94 0x1B 0x1>;
            pinctrl-names = "default";
            pinctrl-0 = <0x95>;
            panel_description = "G size=153,85 delays=20,20,20,120,20 format=rgb888 lanes=4 flags=0xe03", "M clock=50000 horizontal=720,140,80,140 vertical=720,20,4,20 default=1", "M clock=50000 horizontal=720,140,100,140 vertical=720,20,150,20", "M clock=50040 horizontal=720,140,112,140 vertical=720,20,140,20", "M clock=51400 horizontal=720,140,132,140 vertical=720,20,148,20", "M clock=50140 horizontal=720,140,90,140 vertical=720,20,40,20", "M clock=56900 horizontal=720,140,90,140 vertical=720,20,114,20", "M clock=50400 horizontal=720,140,92,140 vertical=720,20,10,20", "M clock=50220 horizontal=720,140,80,140 vertical=720,20,15,20", "M clock=54600 horizontal=720,140,112,140 vertical=720,20,57,20", "M clock=75450 horizontal=720,140,95,140 vertical=720,20,153,20", "M clock=75330 horizontal=720,140,80,140 vertical=720,20,15,20", "M clock=100440 horizontal=720,140,80,140 vertical=720,20,15,20", "I seq=b9f11283", "I seq=b1000000da80", "I seq=b23c1230", "I seq=b31010282803ff00000000", "I seq=b480", "I seq=b50a0a", "I seq=b69797", "I seq=b82622f013", "I seq=ba338105f90e0e2000000000000000442500900a0000014f01000037", "I seq=bc47", "I seq=bf021100", "I seq=c0737350500000127000", "I seq=c12500323277e4ffffcccc7777", "I seq=c68200bfff00ff", "I seq=c7b8000a000000", "I seq=c810401e02", "I seq=cc0b", "I seq=e0000b102c3d3f423a070d0f131513140f16000b102c3d3f423a070d0f131513140f16", "I seq=e307070b0b0b0b00000000ff00c010", "I seq=e9c8100a000080811231234f86a000470800000c00000000000c00000098028baf4602888888888898138baf5713888888888800000000000000000000000000", "I seq=ea970c090909780000000000009f318ba8317588888888889f208ba820648888888888230000027100000000000000000000000000000040808100000000", "I seq=efffff01", "I seq=11 wait=250", "I seq=29 wait=50";
            phandle = <0xF2>;
            enable-gpios = <0x94 0x3 0x0>;
            port {
                endpoint {
                    remote-endpoint = <0x96>;
                    phandle = <0x91>;
                };
            };
        };
    };
    vop@ff460000 {
        compatible = "rockchip,px30-vop-big";
        reg = <0x0 0xFF460000 0x0 0xEFC>;
        interrupts = <0x0 0x4D 0x4>;
        clocks = <0x2 0xB5 0x2 0x96 0x2 0xFB>;
        clock-names = "aclk_vop", "dclk_vop", "hclk_vop";
        resets = <0x2 0x33 0x2 0x34 0x2 0x35>;
        reset-names = "axi", "ahb", "dclk";
        iommus = <0x97>;
        power-domains = <0x71 0xC>;
        status = "okay";
        phandle = <0xF3>;
        port {
            #address-cells = <0x1>;
            #size-cells = <0x0>;
            phandle = <0xB>;
            endpoint@0 {
                reg = <0x0>;
                remote-endpoint = <0x98>;
                phandle = <0x90>;
            };
            endpoint@1 {
                reg = <0x1>;
                remote-endpoint = <0x99>;
                phandle = <0x44>;
            };
        };
    };
    iommu@ff460f00 {
        compatible = "rockchip,iommu";
        reg = <0x0 0xFF460F00 0x0 0x100>;
        interrupts = <0x0 0x4D 0x4>;
        clocks = <0x2 0xB5 0x2 0xFB>;
        clock-names = "aclk", "iface";
        power-domains = <0x71 0xC>;
        #iommu-cells = <0x0>;
        status = "okay";
        phandle = <0x97>;
    };
    video-capture@ff490000 {
        compatible = "rockchip,px30-vip";
        reg = <0x0 0xFF490000 0x0 0x200>;
        interrupts = <0x0 0x45 0x4>;
        clocks = <0x2 0xB3 0x2 0xF9 0x2 0x160>;
        clock-names = "aclk", "hclk", "pclk";
        power-domains = <0x71 0xD>;
        resets = <0x2 0x2C 0x2 0x2D 0x2 0x2E>;
        reset-names = "axi", "ahb", "pclkin";
        status = "disabled";
        phandle = <0xF4>;
    };
    isp@ff4a0000 {
        compatible = "rockchip,px30-cif-isp";
        reg = <0x0 0xFF4A0000 0x0 0x8000>;
        interrupts = <0x0 0x46 0x4 0x0 0x49 0x4 0x0 0x4A 0x4>;
        interrupt-names = "isp", "mi", "mipi";
        clocks = <0x2 0x33 0x2 0xB4 0x2 0xFA 0x2 0x15F>;
        clock-names = "isp", "aclk", "hclk", "pclk";
        iommus = <0x9A>;
        phys = <0x9B>;
        phy-names = "dphy";
        power-domains = <0x71 0xD>;
        status = "okay";
        phandle = <0xF5>;
        ports {
            #address-cells = <0x1>;
            #size-cells = <0x0>;
            port@0 {
                reg = <0x0>;
                phandle = <0xF6>;
            };
        };
    };
    iommu@ff4a8000 {
        compatible = "rockchip,iommu";
        reg = <0x0 0xFF4A8000 0x0 0x100>;
        interrupts = <0x0 0x46 0x4>;
        clocks = <0x2 0xB4 0x2 0xFA>;
        clock-names = "aclk", "iface";
        power-domains = <0x71 0xD>;
        rockchip,disable-mmu-reset;
        #iommu-cells = <0x0>;
        status = "okay";
        phandle = <0x9A>;
    };
    qos@ff518000 {
        compatible = "rockchip,px30-qos", "syscon";
        reg = <0x0 0xFF518000 0x0 0x20>;
        phandle = <0x13>;
    };
    qos@ff520000 {
        compatible = "rockchip,px30-qos", "syscon";
        reg = <0x0 0xFF520000 0x0 0x20>;
        phandle = <0x23>;
    };
    qos@ff52c000 {
        compatible = "rockchip,px30-qos", "syscon";
        reg = <0x0 0xFF52C000 0x0 0x20>;
        phandle = <0x12>;
    };
    qos@ff538000 {
        compatible = "rockchip,px30-qos", "syscon";
        reg = <0x0 0xFF538000 0x0 0x20>;
        phandle = <0x14>;
    };
    qos@ff538080 {
        compatible = "rockchip,px30-qos", "syscon";
        reg = <0x0 0xFF538080 0x0 0x20>;
        phandle = <0x15>;
    };
    qos@ff538100 {
        compatible = "rockchip,px30-qos", "syscon";
        reg = <0x0 0xFF538100 0x0 0x20>;
        phandle = <0x16>;
    };
    qos@ff538180 {
        compatible = "rockchip,px30-qos", "syscon";
        reg = <0x0 0xFF538180 0x0 0x20>;
        phandle = <0x17>;
    };
    qos@ff540000 {
        compatible = "rockchip,px30-qos", "syscon";
        reg = <0x0 0xFF540000 0x0 0x20>;
        phandle = <0x10>;
    };
    qos@ff540080 {
        compatible = "rockchip,px30-qos", "syscon";
        reg = <0x0 0xFF540080 0x0 0x20>;
        phandle = <0x11>;
    };
    qos@ff548000 {
        compatible = "rockchip,px30-qos", "syscon";
        reg = <0x0 0xFF548000 0x0 0x20>;
        phandle = <0x1E>;
    };
    qos@ff548080 {
        compatible = "rockchip,px30-qos", "syscon";
        reg = <0x0 0xFF548080 0x0 0x20>;
        phandle = <0x1F>;
    };
    qos@ff548100 {
        compatible = "rockchip,px30-qos", "syscon";
        reg = <0x0 0xFF548100 0x0 0x20>;
        phandle = <0x20>;
    };
    qos@ff548180 {
        compatible = "rockchip,px30-qos", "syscon";
        reg = <0x0 0xFF548180 0x0 0x20>;
        phandle = <0x21>;
    };
    qos@ff548200 {
        compatible = "rockchip,px30-qos", "syscon";
        reg = <0x0 0xFF548200 0x0 0x20>;
        phandle = <0x22>;
    };
    qos@ff550000 {
        compatible = "rockchip,px30-qos", "syscon";
        reg = <0x0 0xFF550000 0x0 0x20>;
        phandle = <0x1A>;
    };
    qos@ff550080 {
        compatible = "rockchip,px30-qos", "syscon";
        reg = <0x0 0xFF550080 0x0 0x20>;
        phandle = <0x1B>;
    };
    qos@ff550100 {
        compatible = "rockchip,px30-qos", "syscon";
        reg = <0x0 0xFF550100 0x0 0x20>;
        phandle = <0x1C>;
    };
    qos@ff550180 {
        compatible = "rockchip,px30-qos", "syscon";
        reg = <0x0 0xFF550180 0x0 0x20>;
        phandle = <0x1D>;
    };
    qos@ff558000 {
        compatible = "rockchip,px30-qos", "syscon";
        reg = <0x0 0xFF558000 0x0 0x20>;
        phandle = <0x18>;
    };
    qos@ff558080 {
        compatible = "rockchip,px30-qos", "syscon";
        reg = <0x0 0xFF558080 0x0 0x20>;
        phandle = <0x19>;
    };
    pinctrl {
        compatible = "rockchip,px30-pinctrl";
        rockchip,grf = <0x2A>;
        rockchip,pmu = <0x9C>;
        #address-cells = <0x2>;
        #size-cells = <0x2>;
        ranges;
        phandle = <0xF7>;
        gpio@ff040000 {
            compatible = "rockchip,gpio-bank";
            reg = <0x0 0xFF040000 0x0 0x100>;
            interrupts = <0x0 0x3 0x4>;
            clocks = <0x25 0x14>;
            gpio-controller;
            #gpio-cells = <0x2>;
            interrupt-controller;
            #interrupt-cells = <0x2>;
            phandle = <0x53>;
        };
        gpio@ff250000 {
            compatible = "rockchip,gpio-bank";
            reg = <0x0 0xFF250000 0x0 0x100>;
            interrupts = <0x0 0x4 0x4>;
            clocks = <0x2 0x15C>;
            gpio-controller;
            #gpio-cells = <0x2>;
            interrupt-controller;
            #interrupt-cells = <0x2>;
            phandle = <0xF8>;
        };
        gpio@ff260000 {
            compatible = "rockchip,gpio-bank";
            reg = <0x0 0xFF260000 0x0 0x100>;
            interrupts = <0x0 0x5 0x4>;
            clocks = <0x2 0x15D>;
            gpio-controller;
            #gpio-cells = <0x2>;
            interrupt-controller;
            #interrupt-cells = <0x2>;
            phandle = <0xAA>;
        };
        gpio@ff270000 {
            compatible = "rockchip,gpio-bank";
            reg = <0x0 0xFF270000 0x0 0x100>;
            interrupts = <0x0 0x6 0x4>;
            clocks = <0x2 0x15E>;
            gpio-controller;
            #gpio-cells = <0x2>;
            interrupt-controller;
            #interrupt-cells = <0x2>;
            phandle = <0x94>;
        };
        pcfg-pull-up {
            bias-pull-up;
            phandle = <0x9F>;
        };
        pcfg-pull-down {
            bias-pull-down;
            phandle = <0xF9>;
        };
        pcfg-pull-none {
            bias-disable;
            phandle = <0x9E>;
        };
        pcfg-pull-none-2ma {
            bias-disable;
            drive-strength = <0x2>;
            phandle = <0xFA>;
        };
        pcfg-pull-up-2ma {
            bias-pull-up;
            drive-strength = <0x2>;
            phandle = <0xFB>;
        };
        pcfg-pull-up-4ma {
            bias-pull-up;
            drive-strength = <0x4>;
            phandle = <0xA0>;
        };
        pcfg-pull-none-4ma {
            bias-disable;
            drive-strength = <0x4>;
            phandle = <0xFC>;
        };
        pcfg-pull-down-4ma {
            bias-pull-down;
            drive-strength = <0x4>;
            phandle = <0xFD>;
        };
        pcfg-pull-none-8ma {
            bias-disable;
            drive-strength = <0x8>;
            phandle = <0xA3>;
        };
        pcfg-pull-up-8ma {
            bias-pull-up;
            drive-strength = <0x8>;
            phandle = <0xA1>;
        };
        pcfg-pull-none-12ma {
            bias-disable;
            drive-strength = <0xC>;
            phandle = <0xA5>;
        };
        pcfg-pull-up-12ma {
            bias-pull-up;
            drive-strength = <0xC>;
            phandle = <0xA4>;
        };
        pcfg-pull-none-smt {
            bias-disable;
            input-schmitt-enable;
            phandle = <0x9D>;
        };
        pcfg-output-high {
            output-high;
            phandle = <0xFE>;
        };
        pcfg-output-low {
            output-low;
            phandle = <0xA6>;
        };
        pcfg-input-high {
            bias-pull-up;
            input-enable;
            phandle = <0xA2>;
        };
        pcfg-input {
            input-enable;
            phandle = <0xFF>;
        };
        i2c0 {
            i2c0-xfer {
                rockchip,pins = <0x0 0x8 0x1 0x9D 0x0 0x9 0x1 0x9D>;
                phandle = <0x52>;
            };
        };
        i2c1 {
            i2c1-xfer {
                rockchip,pins = <0x0 0x12 0x1 0x9D 0x0 0x13 0x1 0x9D>;
                phandle = <0x58>;
            };
        };
        i2c2 {
            i2c2-xfer {
                rockchip,pins = <0x2 0xF 0x2 0x9D 0x2 0x10 0x2 0x9D>;
                phandle = <0x59>;
            };
        };
        i2c3 {
            i2c3-xfer {
                rockchip,pins = <0x1 0xC 0x4 0x9D 0x1 0xD 0x4 0x9D>;
                phandle = <0x5A>;
            };
        };
        tsadc {
            tsadc-otp-pin {
                rockchip,pins = <0x0 0x6 0x0 0x9E>;
                phandle = <0x6C>;
            };
            tsadc-otp-out {
                rockchip,pins = <0x0 0x6 0x1 0x9E>;
                phandle = <0x6D>;
            };
        };
        uart0 {
            uart0-xfer {
                rockchip,pins = <0x0 0xA 0x1 0x9F 0x0 0xB 0x1 0x9F>;
                phandle = <0x27>;
            };
            uart0-cts {
                rockchip,pins = <0x0 0xC 0x1 0x9E>;
                phandle = <0x28>;
            };
            uart0-rts {
                rockchip,pins = <0x0 0xD 0x1 0x9E>;
                phandle = <0x29>;
            };
        };
        uart1 {
            uart1-xfer {
                rockchip,pins = <0x1 0x11 0x1 0x9F 0x1 0x10 0x1 0x9F>;
                phandle = <0x45>;
            };
            uart1-cts {
                rockchip,pins = <0x1 0x12 0x1 0x9E>;
                phandle = <0x46>;
            };
            uart1-rts {
                rockchip,pins = <0x1 0x13 0x1 0x9E>;
                phandle = <0x47>;
            };
        };
        uart2-m0 {
            uart2m0-xfer {
                rockchip,pins = <0x1 0x1A 0x2 0x9F 0x1 0x1B 0x2 0x9F>;
                phandle = <0x48>;
            };
        };
        uart2-m1 {
            uart2m1-xfer {
                rockchip,pins = <0x2 0xC 0x2 0x9F 0x2 0xE 0x2 0x9F>;
                phandle = <0x100>;
            };
        };
        uart3-m0 {
            uart3m0-xfer {
                rockchip,pins = <0x0 0x10 0x2 0x9F 0x0 0x11 0x2 0x9F>;
                phandle = <0x101>;
            };
            uart3m0-cts {
                rockchip,pins = <0x0 0x12 0x2 0x9E>;
                phandle = <0x102>;
            };
            uart3m0-rts {
                rockchip,pins = <0x0 0x13 0x2 0x9E>;
                phandle = <0x103>;
            };
        };
        uart3-m1 {
            uart3m1-xfer {
                rockchip,pins = <0x1 0xE 0x2 0x9F 0x1 0xF 0x2 0x9F>;
                phandle = <0x49>;
            };
            uart3m1-cts {
                rockchip,pins = <0x1 0xC 0x2 0x9E>;
                phandle = <0x4A>;
            };
            uart3m1-rts {
                rockchip,pins = <0x1 0xD 0x2 0x9E>;
                phandle = <0x4B>;
            };
        };
        uart4 {
            uart4-xfer {
                rockchip,pins = <0x1 0x1C 0x2 0x9F 0x1 0x1D 0x2 0x9F>;
                phandle = <0x4C>;
            };
            uart4-cts {
                rockchip,pins = <0x1 0x1E 0x2 0x9E>;
                phandle = <0x4D>;
            };
            uart4-rts {
                rockchip,pins = <0x1 0x1F 0x2 0x9E>;
                phandle = <0x4E>;
            };
        };
        uart5 {
            uart5-xfer {
                rockchip,pins = <0x3 0x2 0x4 0x9F 0x3 0x1 0x4 0x9F>;
                phandle = <0x4F>;
            };
            uart5-cts {
                rockchip,pins = <0x3 0x3 0x4 0x9E>;
                phandle = <0x50>;
            };
            uart5-rts {
                rockchip,pins = <0x3 0x5 0x4 0x9E>;
                phandle = <0x51>;
            };
        };
        spi0 {
            spi0-clk {
                rockchip,pins = <0x1 0xF 0x3 0xA0>;
                phandle = <0x5B>;
            };
            spi0-csn {
                rockchip,pins = <0x1 0xE 0x3 0xA0>;
                phandle = <0x5C>;
            };
            spi0-miso {
                rockchip,pins = <0x1 0xD 0x3 0xA0>;
                phandle = <0x5D>;
            };
            spi0-mosi {
                rockchip,pins = <0x1 0xC 0x3 0xA0>;
                phandle = <0x5E>;
            };
            spi0-clk-hs {
                rockchip,pins = <0x1 0xF 0x3 0xA1>;
                phandle = <0x104>;
            };
            spi0-miso-hs {
                rockchip,pins = <0x1 0xD 0x3 0xA1>;
                phandle = <0x105>;
            };
            spi0-mosi-hs {
                rockchip,pins = <0x1 0xC 0x3 0xA1>;
                phandle = <0x106>;
            };
        };
        spi1 {
            spi1-clk {
                rockchip,pins = <0x3 0xF 0x4 0xA0>;
                phandle = <0x5F>;
            };
            spi1-csn0 {
                rockchip,pins = <0x3 0x9 0x4 0xA0>;
                phandle = <0x60>;
            };
            spi1-csn1 {
                rockchip,pins = <0x3 0xA 0x2 0xA0>;
                phandle = <0x61>;
            };
            spi1-miso {
                rockchip,pins = <0x3 0xE 0x4 0xA0>;
                phandle = <0x62>;
            };
            spi1-mosi {
                rockchip,pins = <0x3 0xC 0x4 0xA0>;
                phandle = <0x63>;
            };
            spi1-clk-hs {
                rockchip,pins = <0x3 0xF 0x4 0xA1>;
                phandle = <0x107>;
            };
            spi1-miso-hs {
                rockchip,pins = <0x3 0xE 0x4 0xA1>;
                phandle = <0x108>;
            };
            spi1-mosi-hs {
                rockchip,pins = <0x3 0xC 0x4 0xA1>;
                phandle = <0x109>;
            };
        };
        pdm {
            pdm-clk0m0 {
                rockchip,pins = <0x3 0x16 0x2 0x9E>;
                phandle = <0x10A>;
            };
            pdm-clk0m1 {
                rockchip,pins = <0x2 0x16 0x1 0x9E>;
                phandle = <0x10B>;
            };
            pdm-clk1 {
                rockchip,pins = <0x3 0x17 0x2 0x9E>;
                phandle = <0x10C>;
            };
            pdm-sdi0m0 {
                rockchip,pins = <0x3 0x1B 0x2 0x9E>;
                phandle = <0x10D>;
            };
            pdm-sdi0m1 {
                rockchip,pins = <0x2 0x15 0x2 0x9E>;
                phandle = <0x10E>;
            };
            pdm-sdi1 {
                rockchip,pins = <0x3 0x18 0x2 0x9E>;
                phandle = <0x10F>;
            };
            pdm-sdi2 {
                rockchip,pins = <0x3 0x19 0x2 0x9E>;
                phandle = <0x110>;
            };
            pdm-sdi3 {
                rockchip,pins = <0x3 0x1A 0x2 0x9E>;
                phandle = <0x111>;
            };
            pdm-clk0m0-sleep {
                rockchip,pins = <0x3 0x16 0x0 0xA2>;
                phandle = <0x112>;
            };
            pdm-clk0m1-sleep {
                rockchip,pins = <0x2 0x16 0x0 0xA2>;
                phandle = <0x113>;
            };
            pdm-clk1-sleep {
                rockchip,pins = <0x3 0x17 0x0 0xA2>;
                phandle = <0x114>;
            };
            pdm-sdi0m0-sleep {
                rockchip,pins = <0x3 0x1B 0x0 0xA2>;
                phandle = <0x115>;
            };
            pdm-sdi0m1-sleep {
                rockchip,pins = <0x2 0x15 0x0 0xA2>;
                phandle = <0x116>;
            };
            pdm-sdi1-sleep {
                rockchip,pins = <0x3 0x18 0x0 0xA2>;
                phandle = <0x117>;
            };
            pdm-sdi2-sleep {
                rockchip,pins = <0x3 0x19 0x0 0xA2>;
                phandle = <0x118>;
            };
            pdm-sdi3-sleep {
                rockchip,pins = <0x3 0x1A 0x0 0xA2>;
                phandle = <0x119>;
            };
        };
        i2s0 {
            i2s0-8ch-mclk {
                rockchip,pins = <0x3 0x11 0x2 0x9E>;
                phandle = <0x11A>;
            };
            i2s0-8ch-sclktx {
                rockchip,pins = <0x3 0x13 0x2 0x9E>;
                phandle = <0x2B>;
            };
            i2s0-8ch-sclkrx {
                rockchip,pins = <0x3 0xC 0x2 0x9E>;
                phandle = <0x2C>;
            };
            i2s0-8ch-lrcktx {
                rockchip,pins = <0x3 0x12 0x2 0x9E>;
                phandle = <0x2D>;
            };
            i2s0-8ch-lrckrx {
                rockchip,pins = <0x3 0xD 0x2 0x9E>;
                phandle = <0x2E>;
            };
            i2s0-8ch-sdo0 {
                rockchip,pins = <0x3 0x14 0x2 0x9E>;
                phandle = <0x2F>;
            };
            i2s0-8ch-sdo1 {
                rockchip,pins = <0x3 0x10 0x2 0x9E>;
                phandle = <0x31>;
            };
            i2s0-8ch-sdo2 {
                rockchip,pins = <0x3 0xF 0x2 0x9E>;
                phandle = <0x33>;
            };
            i2s0-8ch-sdo3 {
                rockchip,pins = <0x3 0xE 0x2 0x9E>;
                phandle = <0x35>;
            };
            i2s0-8ch-sdi0 {
                rockchip,pins = <0x3 0x15 0x2 0x9E>;
                phandle = <0x30>;
            };
            i2s0-8ch-sdi1 {
                rockchip,pins = <0x3 0xB 0x2 0x9E>;
                phandle = <0x32>;
            };
            i2s0-8ch-sdi2 {
                rockchip,pins = <0x3 0x9 0x2 0x9E>;
                phandle = <0x34>;
            };
            i2s0-8ch-sdi3 {
                rockchip,pins = <0x3 0x8 0x2 0x9E>;
                phandle = <0x36>;
            };
        };
        i2s1 {
            i2s1-2ch-mclk {
                rockchip,pins = <0x2 0x13 0x1 0x9E>;
                phandle = <0x55>;
            };
            i2s1-2ch-sclk {
                rockchip,pins = <0x2 0x12 0x1 0x9E>;
                phandle = <0x37>;
            };
            i2s1-2ch-lrck {
                rockchip,pins = <0x2 0x11 0x1 0x9E>;
                phandle = <0x38>;
            };
            i2s1-2ch-sdi {
                rockchip,pins = <0x2 0x15 0x1 0x9E>;
                phandle = <0x39>;
            };
            i2s1-2ch-sdo {
                rockchip,pins = <0x2 0x14 0x1 0x9E>;
                phandle = <0x3A>;
            };
        };
        i2s2 {
            i2s2-2ch-mclk {
                rockchip,pins = <0x3 0x1 0x2 0x9E>;
                phandle = <0x11B>;
            };
            i2s2-2ch-sclk {
                rockchip,pins = <0x3 0x2 0x2 0x9E>;
                phandle = <0x3B>;
            };
            i2s2-2ch-lrck {
                rockchip,pins = <0x3 0x3 0x2 0x9E>;
                phandle = <0x3C>;
            };
            i2s2-2ch-sdi {
                rockchip,pins = <0x3 0x5 0x2 0x9E>;
                phandle = <0x3D>;
            };
            i2s2-2ch-sdo {
                rockchip,pins = <0x3 0x7 0x2 0x9E>;
                phandle = <0x3E>;
            };
        };
        sdmmc {
            sdmmc-clk {
                rockchip,pins = <0x1 0x1E 0x1 0xA3>;
                phandle = <0x76>;
            };
            sdmmc-cmd {
                rockchip,pins = <0x1 0x1F 0x1 0xA1>;
                phandle = <0x77>;
            };
            sdmmc-det {
                rockchip,pins = <0x0 0x3 0x1 0xA1>;
                phandle = <0x78>;
            };
            sdmmc-bus1 {
                rockchip,pins = <0x1 0x1A 0x1 0xA1>;
                phandle = <0x11C>;
            };
            sdmmc-bus4 {
                rockchip,pins = <0x1 0x1A 0x1 0xA1 0x1 0x1B 0x1 0xA1 0x1 0x1C 0x1 0xA1 0x1 0x1D 0x1 0xA1>;
                phandle = <0x79>;
            };
        };
        sdio {
            sdio-clk {
                rockchip,pins = <0x1 0x15 0x1 0x9E>;
                phandle = <0x7D>;
            };
            sdio-cmd {
                rockchip,pins = <0x1 0x14 0x1 0x9F>;
                phandle = <0x7C>;
            };
            sdio-bus4 {
                rockchip,pins = <0x1 0x16 0x1 0x9F 0x1 0x17 0x1 0x9F 0x1 0x18 0x1 0x9F 0x1 0x19 0x1 0x9F>;
                phandle = <0x7B>;
            };
        };
        emmc {
            emmc-clk {
                rockchip,pins = <0x1 0x9 0x2 0xA3>;
                phandle = <0x7F>;
            };
            emmc-cmd {
                rockchip,pins = <0x1 0xA 0x2 0xA1>;
                phandle = <0x80>;
            };
            emmc-rstnout {
                rockchip,pins = <0x1 0xB 0x2 0x9E>;
                phandle = <0x11D>;
            };
            emmc-bus1 {
                rockchip,pins = <0x1 0x0 0x2 0xA1>;
                phandle = <0x11E>;
            };
            emmc-bus4 {
                rockchip,pins = <0x1 0x0 0x2 0xA1 0x1 0x1 0x2 0xA1 0x1 0x2 0x2 0xA1 0x1 0x3 0x2 0xA1>;
                phandle = <0x11F>;
            };
            emmc-bus8 {
                rockchip,pins = <0x1 0x0 0x2 0xA1 0x1 0x1 0x2 0xA1 0x1 0x2 0x2 0xA1 0x1 0x3 0x2 0xA1 0x1 0x4 0x2 0xA1 0x1 0x5 0x2 0xA1 0x1 0x6 0x2 0xA1 0x1 0x7 0x2 0xA1>;
                phandle = <0x81>;
            };
        };
        flash {
            flash-cs0 {
                rockchip,pins = <0x1 0x8 0x1 0x9E>;
                phandle = <0x88>;
            };
            flash-rdy {
                rockchip,pins = <0x1 0x9 0x1 0x9E>;
                phandle = <0x8A>;
            };
            flash-dqs {
                rockchip,pins = <0x1 0xA 0x1 0x9E>;
                phandle = <0x8C>;
            };
            flash-ale {
                rockchip,pins = <0x1 0xB 0x1 0x9E>;
                phandle = <0x85>;
            };
            flash-cle {
                rockchip,pins = <0x1 0xC 0x1 0x9E>;
                phandle = <0x87>;
            };
            flash-wrn {
                rockchip,pins = <0x1 0xD 0x1 0x9E>;
                phandle = <0x8B>;
            };
            flash-csl {
                rockchip,pins = <0x1 0xE 0x1 0x9E>;
                phandle = <0x120>;
            };
            flash-rdn {
                rockchip,pins = <0x1 0xF 0x1 0x9E>;
                phandle = <0x89>;
            };
            flash-bus8 {
                rockchip,pins = <0x1 0x0 0x1 0xA4 0x1 0x1 0x1 0xA4 0x1 0x2 0x1 0xA4 0x1 0x3 0x1 0xA4 0x1 0x4 0x1 0xA4 0x1 0x5 0x1 0xA4 0x1 0x6 0x1 0xA4 0x1 0x7 0x1 0xA4>;
                phandle = <0x86>;
            };
        };
        sfc {
            sfc-bus4 {
                rockchip,pins = <0x1 0x0 0x3 0x9E 0x1 0x1 0x3 0x9E 0x1 0x2 0x3 0x9E 0x1 0x3 0x3 0x9E>;
                phandle = <0x84>;
            };
            sfc-bus2 {
                rockchip,pins = <0x1 0x0 0x3 0x9E 0x1 0x1 0x3 0x9E>;
                phandle = <0x121>;
            };
            sfc-cs0 {
                rockchip,pins = <0x1 0x4 0x3 0x9E>;
                phandle = <0x83>;
            };
            sfc-clk {
                rockchip,pins = <0x1 0x9 0x3 0x9E>;
                phandle = <0x82>;
            };
        };
        lcdc {
            lcdc-rgb-dclk-pin {
                rockchip,pins = <0x3 0x0 0x1 0xA5>;
                phandle = <0x122>;
            };
            lcdc-rgb-m0-hsync-pin {
                rockchip,pins = <0x3 0x1 0x1 0xA5>;
                phandle = <0x123>;
            };
            lcdc-rgb-m0-vsync-pin {
                rockchip,pins = <0x3 0x2 0x1 0xA5>;
                phandle = <0x124>;
            };
            lcdc-rgb-m0-den-pin {
                rockchip,pins = <0x3 0x3 0x1 0xA5>;
                phandle = <0x125>;
            };
            lcdc-rgb888-m0-data-pins {
                rockchip,pins = <0x3 0x7 0x1 0xA3 0x3 0x6 0x1 0xA3 0x3 0x5 0x1 0xA3 0x3 0x4 0x1 0xA3 0x3 0xB 0x1 0xA3 0x3 0xA 0x1 0xA3 0x3 0x9 0x1 0xA3 0x3 0x8 0x1 0xA3 0x3 0xF 0x1 0xA3 0x3 0xE 0x1 0xA3 0x3 0xD 0x1 0xA3 0x3 0xC 0x1 0xA3 0x3 0x13 0x1 0xA3 0x3 0x12 0x1 0xA3 0x3 0x11 0x1 0xA3 0x3 0x10 0x1 0xA3 0x3 0x17 0x1 0xA3 0x3 0x16 0x1 0xA3 0x3 0x15 0x1 0xA3 0x3 0x14 0x1 0xA3 0x3 0x1B 0x1 0xA3 0x3 0x1A 0x1 0xA3 0x3 0x19 0x1 0xA3 0x3 0x18 0x1 0xA3>;
                phandle = <0x126>;
            };
            lcdc-rgb666-m0-data-pins {
                rockchip,pins = <0x3 0x7 0x1 0xA3 0x3 0x6 0x1 0xA3 0x3 0x5 0x1 0xA3 0x3 0x4 0x1 0xA3 0x3 0xB 0x1 0xA3 0x3 0xA 0x1 0xA3 0x3 0x9 0x1 0xA3 0x3 0x8 0x1 0xA3 0x3 0xF 0x1 0xA3 0x3 0xE 0x1 0xA3 0x3 0xD 0x1 0xA3 0x3 0xC 0x1 0xA3 0x3 0x13 0x1 0xA3 0x3 0x12 0x1 0xA3 0x3 0x11 0x1 0xA3 0x3 0x10 0x1 0xA3 0x3 0x15 0x1 0xA3 0x3 0x14 0x1 0xA3>;
                phandle = <0x127>;
            };
            lcdc-rgb565-m0-data-pins {
                rockchip,pins = <0x3 0x7 0x1 0xA3 0x3 0x6 0x1 0xA3 0x3 0x5 0x1 0xA3 0x3 0x4 0x1 0xA3 0x3 0xB 0x1 0xA3 0x3 0xA 0x1 0xA3 0x3 0x9 0x1 0xA3 0x3 0x8 0x1 0xA3 0x3 0xF 0x1 0xA3 0x3 0xE 0x1 0xA3 0x3 0xD 0x1 0xA3 0x3 0xC 0x1 0xA3 0x3 0x13 0x1 0xA3 0x3 0x12 0x1 0xA3 0x3 0x11 0x1 0xA3 0x3 0x10 0x1 0xA3>;
                phandle = <0x128>;
            };
            lcdc-rgb888-m1-data-pins {
                rockchip,pins = <0x3 0x6 0x1 0xA3 0x3 0x4 0x1 0xA3 0x3 0xB 0x1 0xA3 0x3 0xA 0x1 0xA3 0x3 0xD 0x1 0xA3 0x3 0x13 0x1 0xA3 0x3 0x12 0x1 0xA3 0x3 0x11 0x1 0xA3 0x3 0x10 0x1 0xA3 0x3 0x17 0x1 0xA3 0x3 0x16 0x1 0xA3 0x3 0x15 0x1 0xA3 0x3 0x14 0x1 0xA3 0x3 0x1B 0x1 0xA3 0x3 0x1A 0x1 0xA3 0x3 0x19 0x1 0xA3 0x3 0x18 0x1 0xA3>;
                phandle = <0x129>;
            };
            lcdc-rgb666-m1-data-pins {
                rockchip,pins = <0x3 0x6 0x1 0xA3 0x3 0x4 0x1 0xA3 0x3 0xB 0x1 0xA3 0x3 0xA 0x1 0xA3 0x3 0xD 0x1 0xA3 0x3 0x13 0x1 0xA3 0x3 0x12 0x1 0xA3 0x3 0x11 0x1 0xA3 0x3 0x10 0x1 0xA3 0x3 0x15 0x1 0xA3 0x3 0x14 0x1 0xA3>;
                phandle = <0x12A>;
            };
            lcdc-rgb565-m1-data-pins {
                rockchip,pins = <0x3 0x6 0x1 0xA3 0x3 0x4 0x1 0xA3 0x3 0xB 0x1 0xA3 0x3 0xA 0x1 0xA3 0x3 0xD 0x1 0xA3 0x3 0x13 0x1 0xA3 0x3 0x12 0x1 0xA3 0x3 0x11 0x1 0xA3 0x3 0x10 0x1 0xA3>;
                phandle = <0x12B>;
            };
        };
        pwm0 {
            pwm0-pin {
                rockchip,pins = <0x0 0xF 0x1 0x9E>;
                phandle = <0x64>;
            };
        };
        pwm1 {
            pwm1-pin {
                rockchip,pins = <0x0 0x10 0x1 0x9E>;
                phandle = <0x65>;
            };
        };
        pwm2 {
            pwm2-pin {
                rockchip,pins = <0x2 0xD 0x1 0x9E>;
                phandle = <0x66>;
            };
        };
        pwm3 {
            pwm3-pin {
                rockchip,pins = <0x0 0x11 0x1 0x9E>;
                phandle = <0x67>;
            };
        };
        pwm4 {
            pwm4-pin {
                rockchip,pins = <0x3 0x12 0x3 0x9E>;
                phandle = <0x68>;
            };
        };
        pwm5 {
            pwm5-pin {
                rockchip,pins = <0x3 0x13 0x3 0x9E>;
                phandle = <0x69>;
            };
        };
        pwm6 {
            pwm6-pin {
                rockchip,pins = <0x3 0x14 0x3 0x9E>;
                phandle = <0x6A>;
            };
        };
        pwm7 {
            pwm7-pin {
                rockchip,pins = <0x3 0x15 0x3 0x9E>;
                phandle = <0x6B>;
            };
        };
        gmac {
            rmii-pins {
                rockchip,pins = <0x2 0x0 0x2 0xA5 0x2 0x1 0x2 0xA5 0x2 0x2 0x2 0xA5 0x2 0x3 0x2 0x9E 0x2 0x4 0x2 0x9E 0x2 0x5 0x2 0x9E 0x2 0x6 0x2 0x9E 0x2 0x7 0x2 0x9E 0x2 0x9 0x2 0x9E>;
                phandle = <0x74>;
            };
            mac-refclk-12ma {
                rockchip,pins = <0x2 0xA 0x2 0xA5>;
                phandle = <0x75>;
            };
            mac-refclk {
                rockchip,pins = <0x2 0xA 0x2 0x9E>;
                phandle = <0x12C>;
            };
        };
        cif-m0 {
            cif-clkout-m0 {
                rockchip,pins = <0x2 0xB 0x1 0x9E>;
                phandle = <0x12D>;
            };
            dvp-d2d9-m0 {
                rockchip,pins = <0x2 0x0 0x1 0x9E 0x2 0x1 0x1 0x9E 0x2 0x2 0x1 0x9E 0x2 0x3 0x1 0x9E 0x2 0x4 0x1 0x9E 0x2 0x5 0x1 0x9E 0x2 0x6 0x1 0x9E 0x2 0x7 0x1 0x9E 0x2 0x8 0x1 0x9E 0x2 0x9 0x1 0x9E 0x2 0xA 0x1 0x9E 0x2 0xB 0x1 0x9E>;
                phandle = <0x12E>;
            };
            dvp-d0d1-m0 {
                rockchip,pins = <0x2 0xC 0x1 0x9E 0x2 0xE 0x1 0x9E>;
                phandle = <0x12F>;
            };
            d10-d11-m0 {
                rockchip,pins = <0x2 0xF 0x1 0x9E 0x2 0x10 0x1 0x9E>;
                phandle = <0x130>;
            };
        };
        cif-m1 {
            cif-clkout-m1 {
                rockchip,pins = <0x3 0x18 0x3 0x9E>;
                phandle = <0x131>;
            };
            dvp-d2d9-m1 {
                rockchip,pins = <0x3 0x3 0x3 0x9E 0x3 0x5 0x3 0x9E 0x3 0x7 0x3 0x9E 0x3 0x8 0x3 0x9E 0x3 0x9 0x3 0x9E 0x3 0xC 0x3 0x9E 0x3 0xE 0x3 0x9E 0x3 0xF 0x3 0x9E 0x3 0x19 0x3 0x9E 0x3 0x1A 0x3 0x9E 0x3 0x1B 0x3 0x9E 0x3 0x18 0x3 0x9E>;
                phandle = <0x132>;
            };
            dvp-d0d1-m1 {
                rockchip,pins = <0x3 0x1 0x3 0x9E 0x3 0x2 0x3 0x9E>;
                phandle = <0x133>;
            };
            d10-d11-m1 {
                rockchip,pins = <0x3 0x16 0x3 0x9E 0x3 0x17 0x3 0x9E>;
                phandle = <0x134>;
            };
        };
        isp {
            isp-prelight {
                rockchip,pins = <0x3 0x19 0x4 0x9E>;
                phandle = <0x135>;
            };
        };
        btns {
            btn-pins {
                rockchip,pins = <0x2 0xD 0x0 0x9F 0x2 0xE 0x0 0x9F 0x3 0xA 0x0 0x9F 0x3 0xB 0x0 0x9F 0x3 0xC 0x0 0x9F 0x3 0xD 0x0 0x9F 0x3 0xE 0x0 0x9F 0x3 0x10 0x0 0x9F 0x3 0x11 0x0 0x9F 0x3 0x12 0x0 0x9F 0x3 0x13 0x0 0x9F 0x3 0x14 0x0 0x9F 0x3 0x15 0x0 0x9F 0x3 0x16 0x0 0x9F 0x3 0x17 0x0 0x9F 0x3 0x18 0x0 0x9F 0x3 0x19 0x0 0x9F>;
                phandle = <0xA9>;
            };
        };
        headphone {
            hp-det {
                rockchip,pins = <0x2 0x16 0x0 0x9F>;
                phandle = <0xAD>;
            };
        };
        gpio-lcd {
            lcd-rst {
                rockchip,pins = <0x3 0xF 0x0 0x9E>;
                phandle = <0x95>;
            };
        };
        vcc18-lcd {
            vcc18-lcd-n {
                rockchip,pins = <0x0 0xD 0x0 0x9E>;
                phandle = <0xB1>;
            };
        };
        vcc5-usb {
            vcc5-usb {
                rockchip,pins = <0x3 0x4 0x0 0x9E>;
                phandle = <0xB2>;
            };
        };
        gpio-led {
            led-pins {
                rockchip,pins = <0x0 0x0 0x0 0x9E 0x0 0x11 0x0 0x9E>;
                phandle = <0xAB>;
            };
        };
        pmic {
            dc-det {
                rockchip,pins = <0x0 0xB 0x0 0x9E>;
                phandle = <0x136>;
            };
            pmic-int {
                rockchip,pins = <0x0 0xA 0x0 0x9F>;
                phandle = <0x54>;
            };
            soc_slppin_gpio {
                rockchip,pins = <0x0 0x4 0x0 0xA6>;
                phandle = <0x137>;
            };
            soc_slppin_rst {
                rockchip,pins = <0x0 0x4 0x2 0x9E>;
                phandle = <0x138>;
            };
            soc_slppin_slp {
                rockchip,pins = <0x0 0x4 0x1 0x9E>;
                phandle = <0x139>;
            };
        };
        speaker {
            spk-amp-enable-h {
                rockchip,pins = <0x3 0x7 0x0 0x9E>;
                phandle = <0xAC>;
            };
        };
    };
    reserved-memory {
        #address-cells = <0x2>;
        #size-cells = <0x2>;
        ranges;
        linux,cma {
            compatible = "shared-dma-pool";
            reusable;
            size = <0x0 0x4000000>;
            linux,cma-default;
        };
    };
    backlight {
        compatible = "pwm-backlight";
        pwms = <0xA7 0x0 0x61A8 0x0>;
        brightness-levels = <0x0 0x1 0x2 0x3 0x4 0x5 0x6 0x7 0x8 0x9 0xA 0xB 0xC 0xD 0xE 0xF 0x10 0x11 0x12 0x13 0x14 0x15 0x16 0x17 0x18 0x19 0x1A 0x1B 0x1C 0x1D 0x1E 0x1F 0x20 0x21 0x22 0x23 0x24 0x25 0x26 0x27 0x28 0x29 0x2A 0x2B 0x2C 0x2D 0x2E 0x2F 0x30 0x31 0x32 0x33 0x34 0x35 0x36 0x37 0x38 0x39 0x3A 0x3B 0x3C 0x3D 0x3E 0x3F 0x40 0x41 0x42 0x43 0x44 0x45 0x46 0x47 0x48 0x49 0x4A 0x4B 0x4C 0x4D 0x4E 0x4F 0x50 0x51 0x52 0x53 0x54 0x55 0x56 0x57 0x58 0x59 0x5A 0x5B 0x5C 0x5D 0x5E 0x5F 0x60 0x61 0x62 0x63 0x64 0x65 0x66 0x67 0x68 0x69 0x6A 0x6B 0x6C 0x6D 0x6E 0x6F 0x70 0x71 0x72 0x73 0x74 0x75 0x76 0x77 0x78 0x79 0x7A 0x7B 0x7C 0x7D 0x7E 0x7F 0x80 0x81 0x82 0x83 0x84 0x85 0x86 0x87 0x88 0x89 0x8A 0x8B 0x8C 0x8D 0x8E 0x8F 0x90 0x91 0x92 0x93 0x94 0x95 0x96 0x97 0x98 0x99 0x9A 0x9B 0x9C 0x9D 0x9E 0x9F 0xA0 0xA1 0xA2 0xA3 0xA4 0xA5 0xA6 0xA7 0xA8 0xA9 0xAA 0xAB 0xAC 0xAD 0xAE 0xAF 0xB0 0xB1 0xB2 0xB3 0xB4 0xB5 0xB6 0xB7 0xB8 0xB9 0xBA 0xBB 0xBC 0xBD 0xBE 0xBF 0xC0 0xC1 0xC2 0xC3 0xC4 0xC5 0xC6 0xC7 0xC8 0xC9 0xCA 0xCB 0xCC 0xCD 0xCE 0xCF 0xD0 0xD1 0xD2 0xD3 0xD4 0xD5 0xD6 0xD7 0xD8 0xD9 0xDA 0xDB 0xDC 0xDD 0xDE 0xDF 0xE0 0xE1 0xE2 0xE3 0xE4 0xE5 0xE6 0xE7 0xE8 0xE9 0xEA 0xEB 0xEC 0xED 0xEE 0xEF 0xF0 0xF1 0xF2 0xF3 0xF4 0xF5 0xF6 0xF7 0xF8 0xF9 0xFA 0xFB 0xFC 0xFD 0xFE 0xFF>;
        default-brightness-level = <0x80>;
        phandle = <0x93>;
    };
    battery {
        compatible = "simple-battery";
        charge-full-design-microamp-hours = <0x3D0900>;
        charge-term-current-microamp = <0x30D40>;
        constant-charge-current-max-microamp = <0x16E360>;
        constant-charge-voltage-max-microvolt = <0x401640>;
        factory-internal-resistance-micro-ohms = <0x186A0>;
        voltage-max-design-microvolt = <0x3E8FA0>;
        voltage-min-design-microvolt = <0x325AA0>;
        ocv-capacity-celsius = <0x14>;
        ocv-capacity-table-0 = <0x3DC066 0x64 0x3D1080 0x5F 0x3C8B9C 0x5A 0x3C1EA0 0x55 0x3BA970 0x50 0x3B0D30 0x4B 0x3A70F0 0x46 0x39D4B0 0x41 0x393870 0x3C 0x38C340 0x37 0x384E10 0x32 0x37B1D0 0x2D 0x371590 0x28 0x367950 0x23 0x360420 0x1E 0x3567E0 0x19 0x34CBA0 0x14 0x342F60 0xF 0x339320 0xA 0x32F6E0 0x5 0x325AA0 0x0>;
        phandle = <0x57>;
    };
    adc-keys {
        compatible = "adc-keys";
        io-channels = <0xA8 0x2>;
        io-channel-names = "buttons";
        keyup-threshold-microvolt = <0x1B7740>;
        poll-interval = <0x64>;
        status = "disabled";
        phandle = <0x13A>;
        button-vol-up {
            press-threshold-microvolt = <0x3A98>;
            label = "VOLUMEUP";
            linux,code = <0x73>;
        };
        button-vol-down {
            press-threshold-microvolt = <0x493E0>;
            label = "VOLUMEDOWN";
            linux,code = <0x72>;
        };
    };
    joypad {
        compatible = "rocknix-singleadc-joypad";
        joypad-name = "r36s_Gamepad";
        joypad-product = <0x1188>;
        joypad-revision = <0x188>;
        status = "okay";
        pinctrl-names = "default";
        pinctrl-0 = <0xA9>;
        io-channel-names = "amux_adc";
        io-channels = <0xA8 0x1>;
        amux-count = <0x4>;
        amux-channel-mapping = <0x3 0x2 0x0 0x1>;
        amux-en-gpios = <0xAA 0xB 0x1>;
        amux-a-gpios = <0xAA 0x10 0x1>;
        amux-b-gpios = <0xAA 0xF 0x1>;
        button-adc-scale = <0x2>;
        button-adc-deadzone = <0x40>;
        button-adc-fuzz = <0x20>;
        button-adc-flat = <0x20>;
        abs_x-p-tuning = <0xC8>;
        abs_x-n-tuning = <0xC8>;
        abs_y-p-tuning = <0xC8>;
        abs_y-n-tuning = <0xC8>;
        abs_rx-p-tuning = <0xC8>;
        abs_rx-n-tuning = <0xC8>;
        abs_ry-p-tuning = <0xC8>;
        abs_ry-n-tuning = <0xC8>;
        poll-interval = <0xA>;
        phandle = <0x13B>;
        invert-absx;
        invert-absry;
        sw1 {
            gpios = <0x94 0x16 0x1>;
            label = "GPIO DPAD-UP";
            linux,code = <0x220>;
        };
        sw2 {
            gpios = <0x94 0x17 0x1>;
            label = "GPIO DPAD-DOWN";
            linux,code = <0x221>;
        };
        sw3 {
            gpios = <0x94 0x14 0x1>;
            label = "GPIO DPAD-LEFT";
            linux,code = <0x222>;
        };
        sw4 {
            gpios = <0x94 0x15 0x1>;
            label = "GPIO DPAD-RIGHT";
            linux,code = <0x223>;
        };
        sw5 {
            gpios = <0x94 0x10 0x1>;
            label = "GPIO KEY BTN-A";
            linux,code = <0x131>;
        };
        sw6 {
            gpios = <0x94 0x11 0x1>;
            label = "GPIO BTN-B";
            linux,code = <0x130>;
        };
        sw7 {
            gpios = <0x94 0x13 0x1>;
            label = "GPIO BTN-Y";
            linux,code = <0x134>;
        };
        sw8 {
            gpios = <0x94 0x12 0x1>;
            label = "GPIO BTN-X";
            linux,code = <0x133>;
        };
        sw11 {
            gpios = <0xAA 0xD 0x1>;
            label = "GPIO BTN_THUMBL";
            linux,code = <0x13D>;
        };
        sw12 {
            gpios = <0xAA 0xE 0x1>;
            label = "GPIO BTN_THUMBR";
            linux,code = <0x13E>;
        };
        sw13 {
            gpios = <0x94 0x1A 0x1>;
            label = "GPIO BTN_FN";
            linux,code = <0x13C>;
        };
        sw15 {
            gpios = <0x94 0xD 0x1>;
            label = "GPIO TOP-LEFT";
            linux,code = <0x136>;
        };
        sw16 {
            gpios = <0x94 0xB 0x1>;
            label = "GPIO TOP-RIGHT";
            linux,code = <0x137>;
        };
        sw19 {
            gpios = <0x94 0x18 0x1>;
            label = "GPIO BTN_SELECT";
            linux,code = <0x13A>;
        };
        sw20 {
            gpios = <0x94 0x0 0x1>;
            label = "GPIO TOP-RIGHT2";
            linux,code = <0x139>;
        };
        sw21 {
            gpios = <0x94 0x6 0x1>;
            label = "GPIO TOP-LEFT2";
            linux,code = <0x138>;
        };
        sw22 {
            gpios = <0x94 0x19 0x1>;
            label = "GPIO BTN_START";
            linux,code = <0x13B>;
        };
    };
    gpio-leds {
        compatible = "gpio-leds";
        pinctrl-0 = <0xAB>;
        pinctrl-names = "default";
        phandle = <0x13C>;
        led-0 {
            color = <0x1>;
            default-state = "off";
            function = "charging";
            linux,default-trigger = "none";
            gpios = <0x53 0x11 0x0>;
        };
        led-1 {
            color = <0x3>;
            default-state = "on";
            function = "power";
            linux,default-trigger = "default-on";
            gpios = <0x53 0x0 0x0>;
        };
    };
    audio-amplifier {
        compatible = "simple-audio-amplifier";
        enable-gpios = <0x94 0x7 0x0>;
        pinctrl-0 = <0xAC>;
        pinctrl-names = "default";
        sound-name-prefix = "Speaker Amp";
        phandle = <0xAE>;
    };
    rk817-sound-amplified {
        compatible = "simple-audio-card";
        pinctrl-names = "default";
        pinctrl-0 = <0xAD>;
        simple-audio-card,name = "rk817_ext";
        simple-audio-card,aux-devs = <0xAE>;
        simple-audio-card,format = "i2s";
        simple-audio-card,hp-det-gpios = <0xAA 0x16 0x0>;
        simple-audio-card,mclk-fs = <0x100>;
        simple-audio-card,widgets = "Headphone", "Headphones", "Speaker", "Internal Speakers";
        simple-audio-card,routing = "Headphones", "HPOL", "Headphones", "HPOR", "Internal Speakers", "Speaker Amp OUTL", "Internal Speakers", "Speaker Amp OUTR", "Speaker Amp INL", "HPOL", "Speaker Amp INR", "HPOR";
        simple-audio-card,pin-switches = "Internal Speakers";
        status = "okay";
        simple-audio-card,codec {
            sound-dai = <0xAF>;
        };
        simple-audio-card,cpu {
            sound-dai = <0xB0>;
        };
    };
    rk817-sound-simple {
        compatible = "simple-audio-card";
        pinctrl-names = "default";
        pinctrl-0 = <0xAD>;
        simple-audio-card,name = "rk817_ext";
        simple-audio-card,format = "i2s";
        simple-audio-card,hp-det-gpios = <0xAA 0x16 0x0>;
        simple-audio-card,mclk-fs = <0x100>;
        simple-audio-card,widgets = "Headphone", "Headphones", "Speaker", "Internal Speakers";
        simple-audio-card,routing = "Headphones", "HPOL", "Headphones", "HPOR", "Internal Speakers", "SPKO";
        status = "disabled";
        simple-audio-card,codec {
            sound-dai = <0xAF>;
        };
        simple-audio-card,cpu {
            sound-dai = <0xB0>;
        };
    };
    vccsys {
        compatible = "regulator-fixed";
        regulator-name = "vcc5v0_sys";
        regulator-always-on;
        regulator-boot-on;
        regulator-min-microvolt = <0x4C4B40>;
        regulator-max-microvolt = <0x4C4B40>;
        phandle = <0x56>;
    };
    vcc-phy-regulator {
        compatible = "regulator-fixed";
        regulator-name = "vcc_phy";
        regulator-always-on;
        regulator-boot-on;
    };
    vcc18-lcd0 {
        compatible = "regulator-fixed";
        regulator-name = "vcc18_lcd0_n";
        gpio = <0x53 0xD 0x0>;
        enable-active-high;
        pinctrl-0 = <0xB1>;
        pinctrl-names = "default";
        regulator-boot-on;
        phandle = <0x92>;
        regulator-state-mem {
            regulator-off-in-suspend;
        };
    };
    vcc_host {
        compatible = "regulator-fixed";
        regulator-name = "vcc_host";
        regulator-min-microvolt = <0x4C4B40>;
        regulator-max-microvolt = <0x4C4B40>;
        gpio = <0x94 0x4 0x0>;
        pinctrl-0 = <0xB2>;
        pinctrl-names = "default";
        enable-active-high;
        regulator-always-on;
        regulator-boot-on;
        vin-supply = <0xB3>;
        phandle = <0x13D>;
    };
    __symbols__ {
        cpu0 = "/cpus/cpu@0";
        cpu1 = "/cpus/cpu@1";
        cpu2 = "/cpus/cpu@2";
        cpu3 = "/cpus/cpu@3";
        CPU_SLEEP = "/cpus/idle-states/cpu-sleep";
        CLUSTER_SLEEP = "/cpus/idle-states/cluster-sleep";
        cpu0_opp_table = "/opp-table-0";
        display_subsystem = "/display-subsystem";
        gmac_clkin = "/external-gmac-clock";
        thermal_zones = "/thermal-zones";
        soc_thermal = "/thermal-zones/soc-thermal";
        threshold = "/thermal-zones/soc-thermal/trips/trip-point-0";
        target = "/thermal-zones/soc-thermal/trips/trip-point-1";
        soc_crit = "/thermal-zones/soc-thermal/trips/soc-crit";
        gpu_thermal = "/thermal-zones/gpu-thermal";
        gpu_threshold = "/thermal-zones/gpu-thermal/trips/gpu-threshold";
        gpu_target = "/thermal-zones/gpu-thermal/trips/gpu-target";
        gpu_crit = "/thermal-zones/gpu-thermal/trips/gpu-crit";
        xin24m = "/xin24m";
        pmu = "/power-management@ff000000";
        power = "/power-management@ff000000/power-controller";
        pmugrf = "/syscon@ff010000";
        pmu_io_domains = "/syscon@ff010000/io-domains";
        uart0 = "/serial@ff030000";
        i2s0_8ch = "/i2s@ff060000";
        i2s1_2ch = "/i2s@ff070000";
        i2s2_2ch = "/i2s@ff080000";
        gic = "/interrupt-controller@ff131000";
        grf = "/syscon@ff140000";
        io_domains = "/syscon@ff140000/io-domains";
        lvds = "/syscon@ff140000/lvds";
        lvds_in = "/syscon@ff140000/lvds/ports/port@0";
        lvds_vopb_in = "/syscon@ff140000/lvds/ports/port@0/endpoint@0";
        lvds_out = "/syscon@ff140000/lvds/ports/port@1";
        uart1 = "/serial@ff158000";
        uart2 = "/serial@ff160000";
        uart3 = "/serial@ff168000";
        uart4 = "/serial@ff170000";
        uart5 = "/serial@ff178000";
        i2c0 = "/i2c@ff180000";
        rk817 = "/i2c@ff180000/pmic@20";
        vdd_logic = "/i2c@ff180000/pmic@20/regulators/DCDC_REG1";
        vdd_arm = "/i2c@ff180000/pmic@20/regulators/DCDC_REG2";
        vcc_ddr = "/i2c@ff180000/pmic@20/regulators/DCDC_REG3";
        vcc_3v0 = "/i2c@ff180000/pmic@20/regulators/DCDC_REG4";
        vcc_1v0 = "/i2c@ff180000/pmic@20/regulators/LDO_REG1";
        vcc1v8_soc = "/i2c@ff180000/pmic@20/regulators/LDO_REG2";
        vcc1v0_soc = "/i2c@ff180000/pmic@20/regulators/LDO_REG3";
        vcc3v0_pmu = "/i2c@ff180000/pmic@20/regulators/LDO_REG4";
        vccio_sd = "/i2c@ff180000/pmic@20/regulators/LDO_REG5";
        vcc_sd = "/i2c@ff180000/pmic@20/regulators/LDO_REG6";
        vcc2v8_dvp = "/i2c@ff180000/pmic@20/regulators/LDO_REG7";
        vcc3v0_dvp = "/i2c@ff180000/pmic@20/regulators/LDO_REG8";
        vdd1v5_dvp = "/i2c@ff180000/pmic@20/regulators/LDO_REG9";
        usb_midu = "/i2c@ff180000/pmic@20/regulators/BOOST";
        rk817_charger = "/i2c@ff180000/pmic@20/charger";
        rk817_codec = "/i2c@ff180000/pmic@20/codec";
        i2c1 = "/i2c@ff190000";
        i2c2 = "/i2c@ff1a0000";
        i2c3 = "/i2c@ff1b0000";
        spi0 = "/spi@ff1d0000";
        spi1 = "/spi@ff1d8000";
        wdt = "/watchdog@ff1e0000";
        pwm0 = "/pwm@ff200000";
        pwm1 = "/pwm@ff200010";
        pwm2 = "/pwm@ff200020";
        pwm3 = "/pwm@ff200030";
        pwm4 = "/pwm@ff208000";
        pwm5 = "/pwm@ff208010";
        pwm6 = "/pwm@ff208020";
        pwm7 = "/pwm@ff208030";
        rktimer = "/timer@ff210000";
        dmac = "/dma-controller@ff240000";
        tsadc = "/tsadc@ff280000";
        saradc = "/saradc@ff288000";
        otp = "/nvmem@ff290000";
        cpu_id = "/nvmem@ff290000/id@7";
        cpu_leakage = "/nvmem@ff290000/cpu-leakage@17";
        performance = "/nvmem@ff290000/performance@1e";
        cru = "/clock-controller@ff2b0000";
        pmucru = "/clock-controller@ff2bc000";
        usb2phy_grf = "/syscon@ff2c0000";
        u2phy = "/syscon@ff2c0000/usb2phy@100";
        u2phy_host = "/syscon@ff2c0000/usb2phy@100/host-port";
        u2phy_otg = "/syscon@ff2c0000/usb2phy@100/otg-port";
        dsi_dphy = "/phy@ff2e0000";
        csi_dphy = "/phy@ff2f0000";
        usb20_otg = "/usb@ff300000";
        usb_host0_ehci = "/usb@ff340000";
        usb_host0_ohci = "/usb@ff350000";
        gmac = "/ethernet@ff360000";
        mdio = "/ethernet@ff360000/mdio";
        sdmmc = "/mmc@ff370000";
        sdio = "/mmc@ff380000";
        emmc = "/mmc@ff390000";
        sfc = "/spi@ff3a0000";
        nfc = "/nand-controller@ff3b0000";
        gpu_opp_table = "/opp-table-1";
        gpu = "/gpu@ff400000";
        vpu = "/video-codec@ff442000";
        vpu_mmu = "/iommu@ff442800";
        dsi = "/dsi@ff450000";
        dsi_in = "/dsi@ff450000/ports/port@0";
        dsi_in_vopb = "/dsi@ff450000/ports/port@0/endpoint@0";
        mipi_out = "/dsi@ff450000/ports/port@1";
        dsi_out = "/dsi@ff450000/ports/port@1";
        mipi_out_panel = "/dsi@ff450000/ports/port@1/endpoint";
        internal_display = "/dsi@ff450000/panel@0";
        mipi_in_panel = "/dsi@ff450000/panel@0/port/endpoint";
        vopb = "/vop@ff460000";
        vopb_out = "/vop@ff460000/port";
        vopb_out_dsi = "/vop@ff460000/port/endpoint@0";
        vopb_out_lvds = "/vop@ff460000/port/endpoint@1";
        vopb_mmu = "/iommu@ff460f00";
        cif = "/video-capture@ff490000";
        isp = "/isp@ff4a0000";
        isp_in = "/isp@ff4a0000/ports/port@0";
        isp_mmu = "/iommu@ff4a8000";
        qos_gmac = "/qos@ff518000";
        qos_gpu = "/qos@ff520000";
        qos_sdmmc = "/qos@ff52c000";
        qos_emmc = "/qos@ff538000";
        qos_nand = "/qos@ff538080";
        qos_sdio = "/qos@ff538100";
        qos_sfc = "/qos@ff538180";
        qos_usb_host = "/qos@ff540000";
        qos_usb_otg = "/qos@ff540080";
        qos_isp_128 = "/qos@ff548000";
        qos_isp_rd = "/qos@ff548080";
        qos_isp_wr = "/qos@ff548100";
        qos_isp_m1 = "/qos@ff548180";
        qos_vip = "/qos@ff548200";
        qos_rga_rd = "/qos@ff550000";
        qos_rga_wr = "/qos@ff550080";
        qos_vop_m0 = "/qos@ff550100";
        qos_vop_m1 = "/qos@ff550180";
        qos_vpu = "/qos@ff558000";
        qos_vpu_r128 = "/qos@ff558080";
        pinctrl = "/pinctrl";
        gpio0 = "/pinctrl/gpio@ff040000";
        gpio1 = "/pinctrl/gpio@ff250000";
        gpio2 = "/pinctrl/gpio@ff260000";
        gpio3 = "/pinctrl/gpio@ff270000";
        pcfg_pull_up = "/pinctrl/pcfg-pull-up";
        pcfg_pull_down = "/pinctrl/pcfg-pull-down";
        pcfg_pull_none = "/pinctrl/pcfg-pull-none";
        pcfg_pull_none_2ma = "/pinctrl/pcfg-pull-none-2ma";
        pcfg_pull_up_2ma = "/pinctrl/pcfg-pull-up-2ma";
        pcfg_pull_up_4ma = "/pinctrl/pcfg-pull-up-4ma";
        pcfg_pull_none_4ma = "/pinctrl/pcfg-pull-none-4ma";
        pcfg_pull_down_4ma = "/pinctrl/pcfg-pull-down-4ma";
        pcfg_pull_none_8ma = "/pinctrl/pcfg-pull-none-8ma";
        pcfg_pull_up_8ma = "/pinctrl/pcfg-pull-up-8ma";
        pcfg_pull_none_12ma = "/pinctrl/pcfg-pull-none-12ma";
        pcfg_pull_up_12ma = "/pinctrl/pcfg-pull-up-12ma";
        pcfg_pull_none_smt = "/pinctrl/pcfg-pull-none-smt";
        pcfg_output_high = "/pinctrl/pcfg-output-high";
        pcfg_output_low = "/pinctrl/pcfg-output-low";
        pcfg_input_high = "/pinctrl/pcfg-input-high";
        pcfg_input = "/pinctrl/pcfg-input";
        i2c0_xfer = "/pinctrl/i2c0/i2c0-xfer";
        i2c1_xfer = "/pinctrl/i2c1/i2c1-xfer";
        i2c2_xfer = "/pinctrl/i2c2/i2c2-xfer";
        i2c3_xfer = "/pinctrl/i2c3/i2c3-xfer";
        tsadc_otp_pin = "/pinctrl/tsadc/tsadc-otp-pin";
        tsadc_otp_out = "/pinctrl/tsadc/tsadc-otp-out";
        uart0_xfer = "/pinctrl/uart0/uart0-xfer";
        uart0_cts = "/pinctrl/uart0/uart0-cts";
        uart0_rts = "/pinctrl/uart0/uart0-rts";
        uart1_xfer = "/pinctrl/uart1/uart1-xfer";
        uart1_cts = "/pinctrl/uart1/uart1-cts";
        uart1_rts = "/pinctrl/uart1/uart1-rts";
        uart2m0_xfer = "/pinctrl/uart2-m0/uart2m0-xfer";
        uart2m1_xfer = "/pinctrl/uart2-m1/uart2m1-xfer";
        uart3m0_xfer = "/pinctrl/uart3-m0/uart3m0-xfer";
        uart3m0_cts = "/pinctrl/uart3-m0/uart3m0-cts";
        uart3m0_rts = "/pinctrl/uart3-m0/uart3m0-rts";
        uart3m1_xfer = "/pinctrl/uart3-m1/uart3m1-xfer";
        uart3m1_cts = "/pinctrl/uart3-m1/uart3m1-cts";
        uart3m1_rts = "/pinctrl/uart3-m1/uart3m1-rts";
        uart4_xfer = "/pinctrl/uart4/uart4-xfer";
        uart4_cts = "/pinctrl/uart4/uart4-cts";
        uart4_rts = "/pinctrl/uart4/uart4-rts";
        uart5_xfer = "/pinctrl/uart5/uart5-xfer";
        uart5_cts = "/pinctrl/uart5/uart5-cts";
        uart5_rts = "/pinctrl/uart5/uart5-rts";
        spi0_clk = "/pinctrl/spi0/spi0-clk";
        spi0_csn = "/pinctrl/spi0/spi0-csn";
        spi0_miso = "/pinctrl/spi0/spi0-miso";
        spi0_mosi = "/pinctrl/spi0/spi0-mosi";
        spi0_clk_hs = "/pinctrl/spi0/spi0-clk-hs";
        spi0_miso_hs = "/pinctrl/spi0/spi0-miso-hs";
        spi0_mosi_hs = "/pinctrl/spi0/spi0-mosi-hs";
        spi1_clk = "/pinctrl/spi1/spi1-clk";
        spi1_csn0 = "/pinctrl/spi1/spi1-csn0";
        spi1_csn1 = "/pinctrl/spi1/spi1-csn1";
        spi1_miso = "/pinctrl/spi1/spi1-miso";
        spi1_mosi = "/pinctrl/spi1/spi1-mosi";
        spi1_clk_hs = "/pinctrl/spi1/spi1-clk-hs";
        spi1_miso_hs = "/pinctrl/spi1/spi1-miso-hs";
        spi1_mosi_hs = "/pinctrl/spi1/spi1-mosi-hs";
        pdm_clk0m0 = "/pinctrl/pdm/pdm-clk0m0";
        pdm_clk0m1 = "/pinctrl/pdm/pdm-clk0m1";
        pdm_clk1 = "/pinctrl/pdm/pdm-clk1";
        pdm_sdi0m0 = "/pinctrl/pdm/pdm-sdi0m0";
        pdm_sdi0m1 = "/pinctrl/pdm/pdm-sdi0m1";
        pdm_sdi1 = "/pinctrl/pdm/pdm-sdi1";
        pdm_sdi2 = "/pinctrl/pdm/pdm-sdi2";
        pdm_sdi3 = "/pinctrl/pdm/pdm-sdi3";
        pdm_clk0m0_sleep = "/pinctrl/pdm/pdm-clk0m0-sleep";
        pdm_clk0m_sleep1 = "/pinctrl/pdm/pdm-clk0m1-sleep";
        pdm_clk1_sleep = "/pinctrl/pdm/pdm-clk1-sleep";
        pdm_sdi0m0_sleep = "/pinctrl/pdm/pdm-sdi0m0-sleep";
        pdm_sdi0m1_sleep = "/pinctrl/pdm/pdm-sdi0m1-sleep";
        pdm_sdi1_sleep = "/pinctrl/pdm/pdm-sdi1-sleep";
        pdm_sdi2_sleep = "/pinctrl/pdm/pdm-sdi2-sleep";
        pdm_sdi3_sleep = "/pinctrl/pdm/pdm-sdi3-sleep";
        i2s0_8ch_mclk = "/pinctrl/i2s0/i2s0-8ch-mclk";
        i2s0_8ch_sclktx = "/pinctrl/i2s0/i2s0-8ch-sclktx";
        i2s0_8ch_sclkrx = "/pinctrl/i2s0/i2s0-8ch-sclkrx";
        i2s0_8ch_lrcktx = "/pinctrl/i2s0/i2s0-8ch-lrcktx";
        i2s0_8ch_lrckrx = "/pinctrl/i2s0/i2s0-8ch-lrckrx";
        i2s0_8ch_sdo0 = "/pinctrl/i2s0/i2s0-8ch-sdo0";
        i2s0_8ch_sdo1 = "/pinctrl/i2s0/i2s0-8ch-sdo1";
        i2s0_8ch_sdo2 = "/pinctrl/i2s0/i2s0-8ch-sdo2";
        i2s0_8ch_sdo3 = "/pinctrl/i2s0/i2s0-8ch-sdo3";
        i2s0_8ch_sdi0 = "/pinctrl/i2s0/i2s0-8ch-sdi0";
        i2s0_8ch_sdi1 = "/pinctrl/i2s0/i2s0-8ch-sdi1";
        i2s0_8ch_sdi2 = "/pinctrl/i2s0/i2s0-8ch-sdi2";
        i2s0_8ch_sdi3 = "/pinctrl/i2s0/i2s0-8ch-sdi3";
        i2s1_2ch_mclk = "/pinctrl/i2s1/i2s1-2ch-mclk";
        i2s1_2ch_sclk = "/pinctrl/i2s1/i2s1-2ch-sclk";
        i2s1_2ch_lrck = "/pinctrl/i2s1/i2s1-2ch-lrck";
        i2s1_2ch_sdi = "/pinctrl/i2s1/i2s1-2ch-sdi";
        i2s1_2ch_sdo = "/pinctrl/i2s1/i2s1-2ch-sdo";
        i2s2_2ch_mclk = "/pinctrl/i2s2/i2s2-2ch-mclk";
        i2s2_2ch_sclk = "/pinctrl/i2s2/i2s2-2ch-sclk";
        i2s2_2ch_lrck = "/pinctrl/i2s2/i2s2-2ch-lrck";
        i2s2_2ch_sdi = "/pinctrl/i2s2/i2s2-2ch-sdi";
        i2s2_2ch_sdo = "/pinctrl/i2s2/i2s2-2ch-sdo";
        sdmmc_clk = "/pinctrl/sdmmc/sdmmc-clk";
        sdmmc_cmd = "/pinctrl/sdmmc/sdmmc-cmd";
        sdmmc_det = "/pinctrl/sdmmc/sdmmc-det";
        sdmmc_bus1 = "/pinctrl/sdmmc/sdmmc-bus1";
        sdmmc_bus4 = "/pinctrl/sdmmc/sdmmc-bus4";
        sdio_clk = "/pinctrl/sdio/sdio-clk";
        sdio_cmd = "/pinctrl/sdio/sdio-cmd";
        sdio_bus4 = "/pinctrl/sdio/sdio-bus4";
        emmc_clk = "/pinctrl/emmc/emmc-clk";
        emmc_cmd = "/pinctrl/emmc/emmc-cmd";
        emmc_rstnout = "/pinctrl/emmc/emmc-rstnout";
        emmc_bus1 = "/pinctrl/emmc/emmc-bus1";
        emmc_bus4 = "/pinctrl/emmc/emmc-bus4";
        emmc_bus8 = "/pinctrl/emmc/emmc-bus8";
        flash_cs0 = "/pinctrl/flash/flash-cs0";
        flash_rdy = "/pinctrl/flash/flash-rdy";
        flash_dqs = "/pinctrl/flash/flash-dqs";
        flash_ale = "/pinctrl/flash/flash-ale";
        flash_cle = "/pinctrl/flash/flash-cle";
        flash_wrn = "/pinctrl/flash/flash-wrn";
        flash_csl = "/pinctrl/flash/flash-csl";
        flash_rdn = "/pinctrl/flash/flash-rdn";
        flash_bus8 = "/pinctrl/flash/flash-bus8";
        sfc_bus4 = "/pinctrl/sfc/sfc-bus4";
        sfc_bus2 = "/pinctrl/sfc/sfc-bus2";
        sfc_cs0 = "/pinctrl/sfc/sfc-cs0";
        sfc_clk = "/pinctrl/sfc/sfc-clk";
        lcdc_rgb_dclk_pin = "/pinctrl/lcdc/lcdc-rgb-dclk-pin";
        lcdc_rgb_m0_hsync_pin = "/pinctrl/lcdc/lcdc-rgb-m0-hsync-pin";
        lcdc_rgb_m0_vsync_pin = "/pinctrl/lcdc/lcdc-rgb-m0-vsync-pin";
        lcdc_rgb_m0_den_pin = "/pinctrl/lcdc/lcdc-rgb-m0-den-pin";
        lcdc_rgb888_m0_data_pins = "/pinctrl/lcdc/lcdc-rgb888-m0-data-pins";
        lcdc_rgb666_m0_data_pins = "/pinctrl/lcdc/lcdc-rgb666-m0-data-pins";
        lcdc_rgb565_m0_data_pins = "/pinctrl/lcdc/lcdc-rgb565-m0-data-pins";
        lcdc_rgb888_m1_data_pins = "/pinctrl/lcdc/lcdc-rgb888-m1-data-pins";
        lcdc_rgb666_m1_data_pins = "/pinctrl/lcdc/lcdc-rgb666-m1-data-pins";
        lcdc_rgb565_m1_data_pins = "/pinctrl/lcdc/lcdc-rgb565-m1-data-pins";
        pwm0_pin = "/pinctrl/pwm0/pwm0-pin";
        pwm1_pin = "/pinctrl/pwm1/pwm1-pin";
        pwm2_pin = "/pinctrl/pwm2/pwm2-pin";
        pwm3_pin = "/pinctrl/pwm3/pwm3-pin";
        pwm4_pin = "/pinctrl/pwm4/pwm4-pin";
        pwm5_pin = "/pinctrl/pwm5/pwm5-pin";
        pwm6_pin = "/pinctrl/pwm6/pwm6-pin";
        pwm7_pin = "/pinctrl/pwm7/pwm7-pin";
        rmii_pins = "/pinctrl/gmac/rmii-pins";
        mac_refclk_12ma = "/pinctrl/gmac/mac-refclk-12ma";
        mac_refclk = "/pinctrl/gmac/mac-refclk";
        cif_clkout_m0 = "/pinctrl/cif-m0/cif-clkout-m0";
        dvp_d2d9_m0 = "/pinctrl/cif-m0/dvp-d2d9-m0";
        dvp_d0d1_m0 = "/pinctrl/cif-m0/dvp-d0d1-m0";
        dvp_d10d11_m0 = "/pinctrl/cif-m0/d10-d11-m0";
        cif_clkout_m1 = "/pinctrl/cif-m1/cif-clkout-m1";
        dvp_d2d9_m1 = "/pinctrl/cif-m1/dvp-d2d9-m1";
        dvp_d0d1_m1 = "/pinctrl/cif-m1/dvp-d0d1-m1";
        dvp_d10d11_m1 = "/pinctrl/cif-m1/d10-d11-m1";
        isp_prelight = "/pinctrl/isp/isp-prelight";
        btn_pins = "/pinctrl/btns/btn-pins";
        hp_det = "/pinctrl/headphone/hp-det";
        lcd_rst = "/pinctrl/gpio-lcd/lcd-rst";
        vcc18_lcd_n = "/pinctrl/vcc18-lcd/vcc18-lcd-n";
        vcc5_usb = "/pinctrl/vcc5-usb/vcc5-usb";
        led_pins = "/pinctrl/gpio-led/led-pins";
        dc_det = "/pinctrl/pmic/dc-det";
        pmic_int = "/pinctrl/pmic/pmic-int";
        soc_slppin_gpio = "/pinctrl/pmic/soc_slppin_gpio";
        soc_slppin_rst = "/pinctrl/pmic/soc_slppin_rst";
        soc_slppin_slp = "/pinctrl/pmic/soc_slppin_slp";
        spk_amp_enable_h = "/pinctrl/speaker/spk-amp-enable-h";
        backlight = "/backlight";
        battery = "/battery";
        adc_keys = "/adc-keys";
        joypad = "/joypad";
        leds = "/gpio-leds";
        spk_amp = "/audio-amplifier";
        vccsys = "/vccsys";
        vcc18_lcd0 = "/vcc18-lcd0";
        vcc_host = "/vcc_host";
    };
};
